[part 1 of 2: package /STELLANTIS/EPT/ASWCs]
AUTOSAR XML (schema 4-2-2)
package /STELLANTIS/EPT/ASWCs
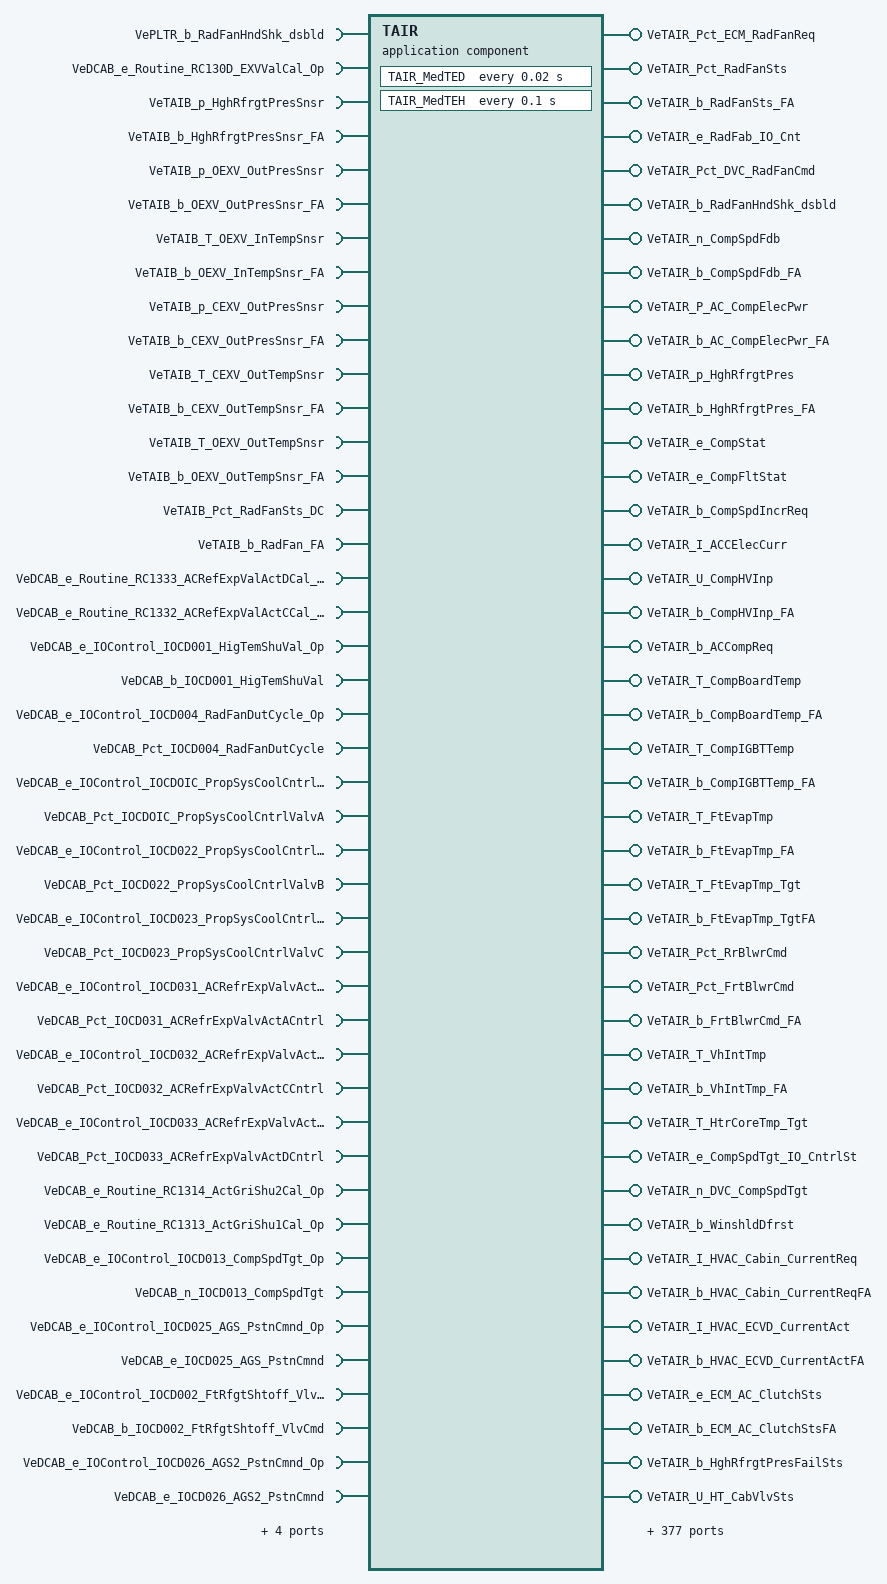
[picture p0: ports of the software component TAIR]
  application sw component type TAIR
    48 x require port:
      VePLTR_b_RadFanHndShk_dsbld: nonqueued-receiver-com-spec{data-element=Value, init-value=0}, required-interface=VePLTR_b_RadFanHndShk_dsbld
      VeDCAB_e_Routine_RC130D_EXVValCal_Op: nonqueued-receiver-com-spec{data-element=Value, init-value=CeDCAB_e_Routine_NOP}, required-interface=VeDCAB_e_Routine_RC130D_EXVValCal_Op
      VeTAIB_p_HghRfrgtPresSnsr: nonqueued-receiver-com-spec{data-element=Value, init-value=0}, required-interface=VeTAIB_p_HghRfrgtPresSnsr
      VeTAIB_b_HghRfrgtPresSnsr_FA: nonqueued-receiver-com-spec{data-element=Value, init-value=0}, required-interface=VeTAIB_b_HghRfrgtPresSnsr_FA
      VeTAIB_p_OEXV_OutPresSnsr: nonqueued-receiver-com-spec{data-element=Value, init-value=0}, required-interface=VeTAIB_p_OEXV_OutPresSnsr
      VeTAIB_b_OEXV_OutPresSnsr_FA: nonqueued-receiver-com-spec{data-element=Value, init-value=0}, required-interface=VeTAIB_b_OEXV_OutPresSnsr_FA
      VeTAIB_T_OEXV_InTempSnsr: nonqueued-receiver-com-spec{data-element=Value, init-value=0}, required-interface=VeTAIB_T_OEXV_InTempSnsr
      VeTAIB_b_OEXV_InTempSnsr_FA: nonqueued-receiver-com-spec{data-element=Value, init-value=0}, required-interface=VeTAIB_b_OEXV_InTempSnsr_FA
      VeTAIB_p_CEXV_OutPresSnsr: nonqueued-receiver-com-spec{data-element=Value, init-value=0}, required-interface=VeTAIB_p_CEXV_OutPresSnsr
      VeTAIB_b_CEXV_OutPresSnsr_FA: nonqueued-receiver-com-spec{data-element=Value, init-value=0}, required-interface=VeTAIB_b_CEXV_OutPresSnsr_FA
      VeTAIB_T_CEXV_OutTempSnsr: nonqueued-receiver-com-spec{data-element=Value, init-value=0}, required-interface=VeTAIB_T_CEXV_OutTempSnsr
      VeTAIB_b_CEXV_OutTempSnsr_FA: nonqueued-receiver-com-spec{data-element=Value, init-value=0}, required-interface=VeTAIB_b_CEXV_OutTempSnsr_FA
      VeTAIB_T_OEXV_OutTempSnsr: nonqueued-receiver-com-spec{data-element=Value, init-value=0}, required-interface=VeTAIB_T_OEXV_OutTempSnsr
      VeTAIB_b_OEXV_OutTempSnsr_FA: nonqueued-receiver-com-spec{data-element=Value, init-value=0}, required-interface=VeTAIB_b_OEXV_OutTempSnsr_FA
      VeTAIB_Pct_RadFanSts_DC: nonqueued-receiver-com-spec{data-element=Value, init-value=0}, required-interface=VeTAIB_Pct_RadFanSts_DC
      VeTAIB_b_RadFan_FA: nonqueued-receiver-com-spec{data-element=Value, init-value=0}, required-interface=VeTAIB_b_RadFan_FA
      VeDCAB_e_Routine_RC1333_ACRefExpValActDCal_Op: nonqueued-receiver-com-spec{data-element=Value, init-value=CeDCAB_e_Routine_NOP}, required-interface=VeDCAB_e_Routine_RC1333_ACRefExpValActDCal_Op
      VeDCAB_e_Routine_RC1332_ACRefExpValActCCal_Op: nonqueued-receiver-com-spec{data-element=Value, init-value=CeDCAB_e_Routine_NOP}, required-interface=VeDCAB_e_Routine_RC1332_ACRefExpValActCCal_Op
      VeDCAB_e_IOControl_IOCD001_HigTemShuVal_Op: nonqueued-receiver-com-spec{data-element=Value, init-value=CeDCAB_e_IO_NOP}, required-interface=VeDCAB_e_IOControl_IOCD001_HigTemShuVal_Op
      VeDCAB_b_IOCD001_HigTemShuVal: nonqueued-receiver-com-spec{data-element=Value, init-value=0}, required-interface=VeDCAB_b_IOCD001_HigTemShuVal
      VeDCAB_e_IOControl_IOCD004_RadFanDutCycle_Op: nonqueued-receiver-com-spec{data-element=Value, init-value=CeDCAB_e_IO_NOP}, required-interface=VeDCAB_e_IOControl_IOCD004_RadFanDutCycle_Op
      VeDCAB_Pct_IOCD004_RadFanDutCycle: nonqueued-receiver-com-spec{data-element=Value, init-value=0}, required-interface=VeDCAB_Pct_IOCD004_RadFanDutCycle
      VeDCAB_e_IOControl_IOCDOIC_PropSysCoolCntrlValvA_Op: nonqueued-receiver-com-spec{data-element=Value, init-value=CeDCAB_e_IO_NOP}, required-interface=VeDCAB_e_IOControl_IOCDOIC_PropSysCoolCntrlValvA_Op
      VeDCAB_Pct_IOCDOIC_PropSysCoolCntrlValvA: nonqueued-receiver-com-spec{data-element=Value, init-value=0}, required-interface=VeDCAB_Pct_IOCDOIC_PropSysCoolCntrlValvA
      VeDCAB_e_IOControl_IOCD022_PropSysCoolCntrlValvB_Op: nonqueued-receiver-com-spec{data-element=Value, init-value=CeDCAB_e_IO_NOP}, required-interface=VeDCAB_e_IOControl_IOCD022_PropSysCoolCntrlValvB_Op
      VeDCAB_Pct_IOCD022_PropSysCoolCntrlValvB: nonqueued-receiver-com-spec{data-element=Value, init-value=0}, required-interface=VeDCAB_Pct_IOCD022_PropSysCoolCntrlValvB
      VeDCAB_e_IOControl_IOCD023_PropSysCoolCntrlValvC_Op: nonqueued-receiver-com-spec{data-element=Value, init-value=CeDCAB_e_IO_NOP}, required-interface=VeDCAB_e_IOControl_IOCD023_PropSysCoolCntrlValvC_Op
      VeDCAB_Pct_IOCD023_PropSysCoolCntrlValvC: nonqueued-receiver-com-spec{data-element=Value, init-value=0}, required-interface=VeDCAB_Pct_IOCD023_PropSysCoolCntrlValvC
      VeDCAB_e_IOControl_IOCD031_ACRefrExpValvActACntrl_Op: nonqueued-receiver-com-spec{data-element=Value, init-value=CeDCAB_e_IO_NOP}, required-interface=VeDCAB_e_IOControl_IOCD031_ACRefrExpValvActACntrl_Op
      VeDCAB_Pct_IOCD031_ACRefrExpValvActACntrl: nonqueued-receiver-com-spec{data-element=Value, init-value=0}, required-interface=VeDCAB_Pct_IOCD031_ACRefrExpValvActACntrl
      VeDCAB_e_IOControl_IOCD032_ACRefrExpValvActCCntrl_Op: nonqueued-receiver-com-spec{data-element=Value, init-value=CeDCAB_e_IO_NOP}, required-interface=VeDCAB_e_IOControl_IOCD032_ACRefrExpValvActCCntrl_Op
      VeDCAB_Pct_IOCD032_ACRefrExpValvActCCntrl: nonqueued-receiver-com-spec{data-element=Value, init-value=0}, required-interface=VeDCAB_Pct_IOCD032_ACRefrExpValvActCCntrl
      VeDCAB_e_IOControl_IOCD033_ACRefrExpValvActDCntrl_Op: nonqueued-receiver-com-spec{data-element=Value, init-value=CeDCAB_e_IO_NOP}, required-interface=VeDCAB_e_IOControl_IOCD033_ACRefrExpValvActDCntrl_Op
      VeDCAB_Pct_IOCD033_ACRefrExpValvActDCntrl: nonqueued-receiver-com-spec{data-element=Value, init-value=0}, required-interface=VeDCAB_Pct_IOCD033_ACRefrExpValvActDCntrl
      VeDCAB_e_Routine_RC1314_ActGriShu2Cal_Op: nonqueued-receiver-com-spec{data-element=Value, init-value=CeDCAB_e_Routine_NOP}, required-interface=VeDCAB_e_Routine_RC1314_ActGriShu2Cal_Op
      VeDCAB_e_Routine_RC1313_ActGriShu1Cal_Op: nonqueued-receiver-com-spec{data-element=Value, init-value=CeDCAB_e_Routine_NOP}, required-interface=VeDCAB_e_Routine_RC1313_ActGriShu1Cal_Op
      VeDCAB_e_IOControl_IOCD013_CompSpdTgt_Op: nonqueued-receiver-com-spec{data-element=Value, init-value=CeDCAB_e_IO_NOP}, required-interface=VeDCAB_e_IOControl_IOCD013_CompSpdTgt_Op
      VeDCAB_n_IOCD013_CompSpdTgt: nonqueued-receiver-com-spec{data-element=Value, init-value=0}, required-interface=VeDCAB_n_IOCD013_CompSpdTgt
      VeDCAB_e_IOControl_IOCD025_AGS_PstnCmnd_Op: nonqueued-receiver-com-spec{data-element=Value, init-value=CeDCAB_e_IO_NOP}, required-interface=VeDCAB_e_IOControl_IOCD025_AGS_PstnCmnd_Op
      VeDCAB_e_IOCD025_AGS_PstnCmnd: nonqueued-receiver-com-spec{data-element=Value, init-value=CeFSCR_e_Open100}, required-interface=VeDCAB_e_IOCD025_AGS_PstnCmnd
      VeDCAB_e_IOControl_IOCD002_FtRfgtShtoff_VlvCmd_Op: nonqueued-receiver-com-spec{data-element=Value, init-value=CeDCAB_e_IO_NOP}, required-interface=VeDCAB_e_IOControl_IOCD002_FtRfgtShtoff_VlvCmd_Op
      VeDCAB_b_IOCD002_FtRfgtShtoff_VlvCmd: nonqueued-receiver-com-spec{data-element=Value, init-value=0}, required-interface=VeDCAB_b_IOCD002_FtRfgtShtoff_VlvCmd
      VeDCAB_e_IOControl_IOCD026_AGS2_PstnCmnd_Op: nonqueued-receiver-com-spec{data-element=Value, init-value=CeDCAB_e_IO_NOP}, required-interface=VeDCAB_e_IOControl_IOCD026_AGS2_PstnCmnd_Op
      VeDCAB_e_IOCD026_AGS2_PstnCmnd: nonqueued-receiver-com-spec{data-element=Value, init-value=CeFSCR_e_Open100}, required-interface=VeDCAB_e_IOCD026_AGS2_PstnCmnd
      VeDCAB_e_IOControl_IOCD01F_ACRefrExpValvActACntrl_Op: nonqueued-receiver-com-spec{data-element=Value, init-value=CeDCAB_e_IO_NOP}, required-interface=VeDCAB_e_IOControl_IOCD01F_ACRefrExpValvActACntrl_Op
      VeDCAB_Pct_IOCD01F_ACRefrExpValvActACntrl: nonqueued-receiver-com-spec{data-element=Value, init-value=0}, required-interface=VeDCAB_Pct_IOCD01F_ACRefrExpValvActACntrl
      VeDCAB_e_IOControl_IOCD007_ChlrRfgtShtoff_VlvCmd_Op: nonqueued-receiver-com-spec{data-element=Value, init-value=CeDCAB_e_IO_NOP}, required-interface=VeDCAB_e_IOControl_IOCD007_ChlrRfgtShtoff_VlvCmd_Op
      VeDCAB_b_IOCD007_ChlrRfgtShtoff_VlvCmd: nonqueued-receiver-com-spec{data-element=Value, init-value=0}, required-interface=VeDCAB_b_IOCD007_ChlrRfgtShtoff_VlvCmd
    421 x provide port:
      VeTAIR_Pct_ECM_RadFanReq: nonqueued-sender-com-spec{data-element=Value, init-value=0}, provided-interface=VeTAIR_Pct_ECM_RadFanReq
      VeTAIR_Pct_RadFanSts: nonqueued-sender-com-spec{data-element=Value, init-value=0}, provided-interface=VeTAIR_Pct_RadFanSts
      VeTAIR_b_RadFanSts_FA: nonqueued-sender-com-spec{data-element=Value, init-value=0}, provided-interface=VeTAIR_b_RadFanSts_FA
      VeTAIR_e_RadFab_IO_Cnt: nonqueued-sender-com-spec{data-element=Value, init-value=CeTAIR_e_Return_Control_to_ECU}, provided-interface=VeTAIR_e_RadFab_IO_Cnt
      VeTAIR_Pct_DVC_RadFanCmd: nonqueued-sender-com-spec{data-element=Value, init-value=0}, provided-interface=VeTAIR_Pct_DVC_RadFanCmd
      VeTAIR_b_RadFanHndShk_dsbld: nonqueued-sender-com-spec{data-element=Value, init-value=0}, provided-interface=VeTAIR_b_RadFanHndShk_dsbld
      VeTAIR_n_CompSpdFdb: nonqueued-sender-com-spec{data-element=Value, init-value=0}, provided-interface=VeTAIR_n_CompSpdFdb
      VeTAIR_b_CompSpdFdb_FA: nonqueued-sender-com-spec{data-element=Value, init-value=0}, provided-interface=VeTAIR_b_CompSpdFdb_FA
      VeTAIR_P_AC_CompElecPwr: nonqueued-sender-com-spec{data-element=Value, init-value=0}, provided-interface=VeTAIR_P_AC_CompElecPwr
      VeTAIR_b_AC_CompElecPwr_FA: nonqueued-sender-com-spec{data-element=Value, init-value=0}, provided-interface=VeTAIR_b_AC_CompElecPwr_FA
      VeTAIR_p_HghRfrgtPres: nonqueued-sender-com-spec{data-element=Value, init-value=0}, provided-interface=VeTAIR_p_HghRfrgtPres
      VeTAIR_b_HghRfrgtPres_FA: nonqueued-sender-com-spec{data-element=Value, init-value=0}, provided-interface=VeTAIR_b_HghRfrgtPres_FA
      VeTAIR_e_CompStat: nonqueued-sender-com-spec{data-element=Value, init-value=CeTAIR_e_NormalOp}, provided-interface=VeTAIR_e_CompStat
      VeTAIR_e_CompFltStat: nonqueued-sender-com-spec{data-element=Value, init-value=CeTAIR_e_CompFltSts_NoFault}, provided-interface=VeTAIR_e_CompFltStat
      VeTAIR_b_CompSpdIncrReq: nonqueued-sender-com-spec{data-element=Value, init-value=0}, provided-interface=VeTAIR_b_CompSpdIncrReq
      VeTAIR_I_ACCElecCurr: nonqueued-sender-com-spec{data-element=Value, init-value=0}, provided-interface=VeTAIR_I_ACCElecCurr
      VeTAIR_U_CompHVInp: nonqueued-sender-com-spec{data-element=Value, init-value=0}, provided-interface=VeTAIR_U_CompHVInp
      VeTAIR_b_CompHVInp_FA: nonqueued-sender-com-spec{data-element=Value, init-value=0}, provided-interface=VeTAIR_b_CompHVInp_FA
      VeTAIR_b_ACCompReq: nonqueued-sender-com-spec{data-element=Value, init-value=0}, provided-interface=VeTAIR_b_ACCompReq
      VeTAIR_T_CompBoardTemp: nonqueued-sender-com-spec{data-element=Value, init-value=0}, provided-interface=VeTAIR_T_CompBoardTemp
      VeTAIR_b_CompBoardTemp_FA: nonqueued-sender-com-spec{data-element=Value, init-value=0}, provided-interface=VeTAIR_b_CompBoardTemp_FA
      VeTAIR_T_CompIGBTTemp: nonqueued-sender-com-spec{data-element=Value, init-value=0}, provided-interface=VeTAIR_T_CompIGBTTemp
      VeTAIR_b_CompIGBTTemp_FA: nonqueued-sender-com-spec{data-element=Value, init-value=0}, provided-interface=VeTAIR_b_CompIGBTTemp_FA
      VeTAIR_T_FtEvapTmp: nonqueued-sender-com-spec{data-element=Value, init-value=0}, provided-interface=VeTAIR_T_FtEvapTmp
      VeTAIR_b_FtEvapTmp_FA: nonqueued-sender-com-spec{data-element=Value, init-value=0}, provided-interface=VeTAIR_b_FtEvapTmp_FA
      VeTAIR_T_FtEvapTmp_Tgt: nonqueued-sender-com-spec{data-element=Value, init-value=0}, provided-interface=VeTAIR_T_FtEvapTmp_Tgt
      VeTAIR_b_FtEvapTmp_TgtFA: nonqueued-sender-com-spec{data-element=Value, init-value=0}, provided-interface=VeTAIR_b_FtEvapTmp_TgtFA
      VeTAIR_Pct_RrBlwrCmd: nonqueued-sender-com-spec{data-element=Value, init-value=0}, provided-interface=VeTAIR_Pct_RrBlwrCmd
      VeTAIR_Pct_FrtBlwrCmd: nonqueued-sender-com-spec{data-element=Value, init-value=0}, provided-interface=VeTAIR_Pct_FrtBlwrCmd
      VeTAIR_b_FrtBlwrCmd_FA: nonqueued-sender-com-spec{data-element=Value, init-value=0}, provided-interface=VeTAIR_b_FrtBlwrCmd_FA
      VeTAIR_T_VhIntTmp: nonqueued-sender-com-spec{data-element=Value, init-value=0}, provided-interface=VeTAIR_T_VhIntTmp
      VeTAIR_b_VhIntTmp_FA: nonqueued-sender-com-spec{data-element=Value, init-value=0}, provided-interface=VeTAIR_b_VhIntTmp_FA
      VeTAIR_T_HtrCoreTmp_Tgt: nonqueued-sender-com-spec{data-element=Value, init-value=0}, provided-interface=VeTAIR_T_HtrCoreTmp_Tgt
      VeTAIR_e_CompSpdTgt_IO_CntrlSt: nonqueued-sender-com-spec{data-element=Value, init-value=CeTAIR_e_Return_Control_to_ECU}, provided-interface=VeTAIR_e_CompSpdTgt_IO_CntrlSt
      VeTAIR_n_DVC_CompSpdTgt: nonqueued-sender-com-spec{data-element=Value, init-value=0}, provided-interface=VeTAIR_n_DVC_CompSpdTgt
      VeTAIR_b_WinshldDfrst: nonqueued-sender-com-spec{data-element=Value, init-value=0}, provided-interface=VeTAIR_b_WinshldDfrst
      VeTAIR_I_HVAC_Cabin_CurrentReq: nonqueued-sender-com-spec{data-element=Value, init-value=0}, provided-interface=VeTAIR_I_HVAC_Cabin_CurrentReq
      VeTAIR_b_HVAC_Cabin_CurrentReqFA: nonqueued-sender-com-spec{data-element=Value, init-value=0}, provided-interface=VeTAIR_b_HVAC_Cabin_CurrentReqFA
      VeTAIR_I_HVAC_ECVD_CurrentAct: nonqueued-sender-com-spec{data-element=Value, init-value=0}, provided-interface=VeTAIR_I_HVAC_ECVD_CurrentAct
      VeTAIR_b_HVAC_ECVD_CurrentActFA: nonqueued-sender-com-spec{data-element=Value, init-value=0}, provided-interface=VeTAIR_b_HVAC_ECVD_CurrentActFA
      VeTAIR_e_ECM_AC_ClutchSts: nonqueued-sender-com-spec{data-element=Value, init-value=CeTAIR_e_ClutchSts_Default}, provided-interface=VeTAIR_e_ECM_AC_ClutchSts
      VeTAIR_b_ECM_AC_ClutchStsFA: nonqueued-sender-com-spec{data-element=Value, init-value=0}, provided-interface=VeTAIR_b_ECM_AC_ClutchStsFA
      VeTAIR_b_HghRfrgtPresFailSts: nonqueued-sender-com-spec{data-element=Value, init-value=0}, provided-interface=VeTAIR_b_HghRfrgtPresFailSts
      VeTAIR_U_HT_CabVlvSts: nonqueued-sender-com-spec{data-element=Value, init-value=0}, provided-interface=VeTAIR_U_HT_CabVlvSts
      VeTAIR_b_HT_CabVlvSts_FA: nonqueued-sender-com-spec{data-element=Value, init-value=0}, provided-interface=VeTAIR_b_HT_CabVlvSts_FA
      VeTAIR_e_DVC_HTCV_CalibStrt: nonqueued-sender-com-spec{data-element=Value, init-value=CeTAIR_e_DVC_HTCV_Calibration_Start}, provided-interface=VeTAIR_e_DVC_HTCV_CalibStrt
      VeTAIR_e_HT_Shtoff_VlvCmd_IO_CntrlSt: nonqueued-sender-com-spec{data-element=Value, init-value=CeTAIR_e_Return_Control_to_ECU}, provided-interface=VeTAIR_e_HT_Shtoff_VlvCmd_IO_CntrlSt
      VeTAIR_b_HT_Shtoff_VlvCmd: nonqueued-sender-com-spec{data-element=Value, init-value=0}, provided-interface=VeTAIR_b_HT_Shtoff_VlvCmd
      VeTAIR_e_Ft_SO_VlvCmd_IO_Cnt: nonqueued-sender-com-spec{data-element=Value, init-value=CeTAIR_e_Return_Control_to_ECU}, provided-interface=VeTAIR_e_Ft_SO_VlvCmd_IO_Cnt
      VeTAIR_b_Ft_SO_VlvCmd: nonqueued-sender-com-spec{data-element=Value, init-value=0}, provided-interface=VeTAIR_b_Ft_SO_VlvCmd
      VeTAIR_e_Chlr_SO_VlvCmd_IO_Cnt: nonqueued-sender-com-spec{data-element=Value, init-value=CeTAIR_e_Return_Control_to_ECU}, provided-interface=VeTAIR_e_Chlr_SO_VlvCmd_IO_Cnt
      VeTAIR_b_Chlr_SO_VlvCmd: nonqueued-sender-com-spec{data-element=Value, init-value=0}, provided-interface=VeTAIR_b_Chlr_SO_VlvCmd
      VeTAIR_e_HT_CabVlvCmd_IO_Cnt: nonqueued-sender-com-spec{data-element=Value, init-value=CeTAIR_e_Return_Control_to_ECU}, provided-interface=VeTAIR_e_HT_CabVlvCmd_IO_Cnt
      VeTAIR_Pct_HT_CabVlvCmd: nonqueued-sender-com-spec{data-element=Value, init-value=0}, provided-interface=VeTAIR_Pct_HT_CabVlvCmd
      VeTAIR_Pct_FrWyVlv_PstnAct: nonqueued-sender-com-spec{data-element=Value, init-value=0}, provided-interface=VeTAIR_Pct_FrWyVlv_PstnAct
      VeTAIR_b_FrWyVlv_PstnAct_FA: nonqueued-sender-com-spec{data-element=Value, init-value=0}, provided-interface=VeTAIR_b_FrWyVlv_PstnAct_FA
      VeTAIR_e_FrWyVlv_CalSts: nonqueued-sender-com-spec{data-element=Value, init-value=CeTAIR_e_CPV_Calibration_Complete}, provided-interface=VeTAIR_e_FrWyVlv_CalSts
      VeTAIR_b_FrWyVlv_RsErr: nonqueued-sender-com-spec{data-element=Value, init-value=0}, provided-interface=VeTAIR_b_FrWyVlv_RsErr
      VeTAIR_e_FrWyVlv_ErrSts: nonqueued-sender-com-spec{data-element=Value, init-value=CeTAIR_e_CPV_Status_OK}, provided-interface=VeTAIR_e_FrWyVlv_ErrSts
      VeTAIR_U_FrWyVlv_MtrVltg: nonqueued-sender-com-spec{data-element=Value, init-value=0}, provided-interface=VeTAIR_U_FrWyVlv_MtrVltg
      VeTAIR_e_CPV_IO_Cnt: nonqueued-sender-com-spec{data-element=Value, init-value=CeTAIR_e_Return_Control_to_ECU}, provided-interface=VeTAIR_e_CPV_IO_Cnt
      VeTAIR_Pct_CPV_Cmd: nonqueued-sender-com-spec{data-element=Value, init-value=0}, provided-interface=VeTAIR_Pct_CPV_Cmd
      VeTAIR_Pct_EXV_PosAct: nonqueued-sender-com-spec{data-element=Value, init-value=0}, provided-interface=VeTAIR_Pct_EXV_PosAct
      VeTAIR_b_EXV_PosAct_FA: nonqueued-sender-com-spec{data-element=Value, init-value=0}, provided-interface=VeTAIR_b_EXV_PosAct_FA
      VeTAIR_e_EXV_CalStat: nonqueued-sender-com-spec{data-element=Value, init-value=CeTAIR_e_EXV_Calibration_Complete}, provided-interface=VeTAIR_e_EXV_CalStat
      VeTAIR_b_EXV_CalRq: nonqueued-sender-com-spec{data-element=Value, init-value=0}, provided-interface=VeTAIR_b_EXV_CalRq
      VeTAIR_b_EXV_RspErr: nonqueued-sender-com-spec{data-element=Value, init-value=0}, provided-interface=VeTAIR_b_EXV_RspErr
      VeTAIR_e_EXV_Sts: nonqueued-sender-com-spec{data-element=Value, init-value=CeTAIR_e_EXV_Status_OK}, provided-interface=VeTAIR_e_EXV_Sts
      VeTAIR_e_EXV_Err: nonqueued-sender-com-spec{data-element=Value, init-value=CeTAIR_e_EXV_ErrorMsg_OK}, provided-interface=VeTAIR_e_EXV_Err
      VeTAIR_U_EXV_SupplyVolt: nonqueued-sender-com-spec{data-element=Value, init-value=0}, provided-interface=VeTAIR_U_EXV_SupplyVolt
      VeTAIR_p_EXV_RefPress: nonqueued-sender-com-spec{data-element=Value, init-value=0}, provided-interface=VeTAIR_p_EXV_RefPress
      VeTAIR_b_EXV_RefPress_FA: nonqueued-sender-com-spec{data-element=Value, init-value=0}, provided-interface=VeTAIR_b_EXV_RefPress_FA
      VeTAIR_T_EXV_BoardTemp: nonqueued-sender-com-spec{data-element=Value, init-value=0}, provided-interface=VeTAIR_T_EXV_BoardTemp
      VeTAIR_T_EXV_RefTemp: nonqueued-sender-com-spec{data-element=Value, init-value=0}, provided-interface=VeTAIR_T_EXV_RefTemp
      VeTAIR_b_EXV_RefTemp_FA: nonqueued-sender-com-spec{data-element=Value, init-value=0}, provided-interface=VeTAIR_b_EXV_RefTemp_FA
      VeTAIR_b_FrWyVlv_OvrVltg: nonqueued-sender-com-spec{data-element=Value, init-value=0}, provided-interface=VeTAIR_b_FrWyVlv_OvrVltg
      VeTAIR_b_FrWyVlv_UndrVltg: nonqueued-sender-com-spec{data-element=Value, init-value=0}, provided-interface=VeTAIR_b_FrWyVlv_UndrVltg
      VeTAIR_b_FrWyVlv_ThrmlWrng: nonqueued-sender-com-spec{data-element=Value, init-value=0}, provided-interface=VeTAIR_b_FrWyVlv_ThrmlWrng
      VeTAIR_b_FrWyVlv_OpnLd: nonqueued-sender-com-spec{data-element=Value, init-value=0}, provided-interface=VeTAIR_b_FrWyVlv_OpnLd
      VeTAIR_b_FrWyVlv_OvrCrnt: nonqueued-sender-com-spec{data-element=Value, init-value=0}, provided-interface=VeTAIR_b_FrWyVlv_OvrCrnt
      VeTAIR_b_FrWyVlv_MechBrk: nonqueued-sender-com-spec{data-element=Value, init-value=0}, provided-interface=VeTAIR_b_FrWyVlv_MechBrk
      VeTAIR_b_FrWyVlv_BlckPnt: nonqueued-sender-com-spec{data-element=Value, init-value=0}, provided-interface=VeTAIR_b_FrWyVlv_BlckPnt
      VeTAIR_b_FrWyVlv_Err_SNA: nonqueued-sender-com-spec{data-element=Value, init-value=0}, provided-interface=VeTAIR_b_FrWyVlv_Err_SNA
      VeTAIR_Pct_LTR_BypsVlv_ActlPstn: nonqueued-sender-com-spec{data-element=Value, init-value=0}, provided-interface=VeTAIR_Pct_LTR_BypsVlv_ActlPstn
      VeTAIR_b_LTR_BypsVlv_ActlPstn_FA: nonqueued-sender-com-spec{data-element=Value, init-value=0}, provided-interface=VeTAIR_b_LTR_BypsVlv_ActlPstn_FA
      VeTAIR_e_LTR_BypsVlv_CalSts: nonqueued-sender-com-spec{data-element=Value, init-value=CeTAIR_e_CPV_Calibration_Complete}, provided-interface=VeTAIR_e_LTR_BypsVlv_CalSts
      VeTAIR_b_LTR_BypsVlv_CalSts_FA: nonqueued-sender-com-spec{data-element=Value, init-value=0}, provided-interface=VeTAIR_b_LTR_BypsVlv_CalSts_FA
      VeTAIR_b_LTR_BypsVlv_RsErr: nonqueued-sender-com-spec{data-element=Value, init-value=0}, provided-interface=VeTAIR_b_LTR_BypsVlv_RsErr
      VeTAIR_e_LTR_BypsVlv_ErrSts: nonqueued-sender-com-spec{data-element=Value, init-value=CeTAIR_e_CPV_Status_OK}, provided-interface=VeTAIR_e_LTR_BypsVlv_ErrSts
      VeTAIR_b_LTR_BypsVlv_ErrSts_FA: nonqueued-sender-com-spec{data-element=Value, init-value=0}, provided-interface=VeTAIR_b_LTR_BypsVlv_ErrSts_FA
      VeTAIR_U_LTR_BypsVlv_MtrVltg: nonqueued-sender-com-spec{data-element=Value, init-value=0}, provided-interface=VeTAIR_U_LTR_BypsVlv_MtrVltg
      VeTAIR_b_LTR_BypsVlv_MtrVltg_FA: nonqueued-sender-com-spec{data-element=Value, init-value=0}, provided-interface=VeTAIR_b_LTR_BypsVlv_MtrVltg_FA
      VeTAIR_Pct_HTL_BypsVlv_ActlPstn: nonqueued-sender-com-spec{data-element=Value, init-value=0}, provided-interface=VeTAIR_Pct_HTL_BypsVlv_ActlPstn
      VeTAIR_b_HTL_BypsVlv_ActlPstn_FA: nonqueued-sender-com-spec{data-element=Value, init-value=0}, provided-interface=VeTAIR_b_HTL_BypsVlv_ActlPstn_FA
      VeTAIR_e_HTL_BypsVlv_CalSts: nonqueued-sender-com-spec{data-element=Value, init-value=CeTAIR_e_CPV_Calibration_Complete}, provided-interface=VeTAIR_e_HTL_BypsVlv_CalSts
      VeTAIR_b_HTL_BypsVlv_CalSts_FA: nonqueued-sender-com-spec{data-element=Value, init-value=0}, provided-interface=VeTAIR_b_HTL_BypsVlv_CalSts_FA
      VeTAIR_b_HTL_BypsVlv_RsErr: nonqueued-sender-com-spec{data-element=Value, init-value=0}, provided-interface=VeTAIR_b_HTL_BypsVlv_RsErr
      VeTAIR_e_HTL_BypsVlv_ErrSts: nonqueued-sender-com-spec{data-element=Value, init-value=CeTAIR_e_CPV_Status_OK}, provided-interface=VeTAIR_e_HTL_BypsVlv_ErrSts
      VeTAIR_b_HTL_BypsVlv_ErrSts_FA: nonqueued-sender-com-spec{data-element=Value, init-value=0}, provided-interface=VeTAIR_b_HTL_BypsVlv_ErrSts_FA
      VeTAIR_U_HTL_BypsVlv_MtrVltg: nonqueued-sender-com-spec{data-element=Value, init-value=0}, provided-interface=VeTAIR_U_HTL_BypsVlv_MtrVltg
      VeTAIR_b_HTL_BypsVlv_MtrVltg_FA: nonqueued-sender-com-spec{data-element=Value, init-value=0}, provided-interface=VeTAIR_b_HTL_BypsVlv_MtrVltg_FA
      VeTAIR_e_EXV_IO_CntrlSt: nonqueued-sender-com-spec{data-element=Value, init-value=CeTAIR_e_Return_Control_to_ECU}, provided-interface=VeTAIR_e_EXV_IO_CntrlSt
      VeTAIR_Pct_EXV_Cmd: nonqueued-sender-com-spec{data-element=Value, init-value=0}, provided-interface=VeTAIR_Pct_EXV_Cmd
      VeTAIR_b_DVC_EXV_Calibration_Start: nonqueued-sender-com-spec{data-element=Value, init-value=0}, provided-interface=VeTAIR_b_DVC_EXV_Calibration_Start
      VeTAIR_e_LT_Shtoff_VlvCmd_IO_CntrlSt: nonqueued-sender-com-spec{data-element=Value, init-value=CeTAIR_e_Return_Control_to_ECU}, provided-interface=VeTAIR_e_LT_Shtoff_VlvCmd_IO_CntrlSt
      VeTAIR_b_LT_Shtoff_VlvCmd: nonqueued-sender-com-spec{data-element=Value, init-value=0}, provided-interface=VeTAIR_b_LT_Shtoff_VlvCmd
      VeTAIR_Pct_LTR_BypsVlv_Cmd: nonqueued-sender-com-spec{data-element=Value, init-value=0}, provided-interface=VeTAIR_Pct_LTR_BypsVlv_Cmd
      VeTAIR_e_LTR_BypsVlv_IO_CntrlSt: nonqueued-sender-com-spec{data-element=Value, init-value=CeTAIR_e_Return_Control_to_ECU}, provided-interface=VeTAIR_e_LTR_BypsVlv_IO_CntrlSt
      VeTAIR_Pct_HTL_BypsVlv_Cmd: nonqueued-sender-com-spec{data-element=Value, init-value=0}, provided-interface=VeTAIR_Pct_HTL_BypsVlv_Cmd
      VeTAIR_e_HTL_BypsVlv_IO_CntrlSt: nonqueued-sender-com-spec{data-element=Value, init-value=CeTAIR_e_Return_Control_to_ECU}, provided-interface=VeTAIR_e_HTL_BypsVlv_IO_CntrlSt
      VeTAIR_b_LTR_BypsVlv_OvrVltg: nonqueued-sender-com-spec{data-element=Value, init-value=0}, provided-interface=VeTAIR_b_LTR_BypsVlv_OvrVltg
      VeTAIR_b_LTR_BypsVlv_UndrVltg: nonqueued-sender-com-spec{data-element=Value, init-value=0}, provided-interface=VeTAIR_b_LTR_BypsVlv_UndrVltg
      VeTAIR_b_LTR_BypsVlv_ThrmlWrng: nonqueued-sender-com-spec{data-element=Value, init-value=0}, provided-interface=VeTAIR_b_LTR_BypsVlv_ThrmlWrng
      VeTAIR_b_LTR_BypsVlv_OpnLd: nonqueued-sender-com-spec{data-element=Value, init-value=0}, provided-interface=VeTAIR_b_LTR_BypsVlv_OpnLd
      VeTAIR_b_LTR_BypsVlv_OvrCrnt: nonqueued-sender-com-spec{data-element=Value, init-value=0}, provided-interface=VeTAIR_b_LTR_BypsVlv_OvrCrnt
      VeTAIR_b_LTR_BypsVlv_MechBrk: nonqueued-sender-com-spec{data-element=Value, init-value=0}, provided-interface=VeTAIR_b_LTR_BypsVlv_MechBrk
      VeTAIR_b_LTR_BypsVlv_BlckPnt: nonqueued-sender-com-spec{data-element=Value, init-value=0}, provided-interface=VeTAIR_b_LTR_BypsVlv_BlckPnt
      VeTAIR_b_LTR_BypsVlv_Err_SNA: nonqueued-sender-com-spec{data-element=Value, init-value=0}, provided-interface=VeTAIR_b_LTR_BypsVlv_Err_SNA
      VeTAIR_b_HTL_BypsVlv_OvrVltg: nonqueued-sender-com-spec{data-element=Value, init-value=0}, provided-interface=VeTAIR_b_HTL_BypsVlv_OvrVltg
      VeTAIR_b_HTL_BypsVlv_UndrVltg: nonqueued-sender-com-spec{data-element=Value, init-value=0}, provided-interface=VeTAIR_b_HTL_BypsVlv_UndrVltg
      VeTAIR_b_HTL_BypsVlv_ThrmlWrng: nonqueued-sender-com-spec{data-element=Value, init-value=0}, provided-interface=VeTAIR_b_HTL_BypsVlv_ThrmlWrng
      VeTAIR_b_HTL_BypsVlv_OpnLd: nonqueued-sender-com-spec{data-element=Value, init-value=0}, provided-interface=VeTAIR_b_HTL_BypsVlv_OpnLd
      VeTAIR_b_HTL_BypsVlv_OvrCrnt: nonqueued-sender-com-spec{data-element=Value, init-value=0}, provided-interface=VeTAIR_b_HTL_BypsVlv_OvrCrnt
      VeTAIR_b_HTL_BypsVlv_MechBrk: nonqueued-sender-com-spec{data-element=Value, init-value=0}, provided-interface=VeTAIR_b_HTL_BypsVlv_MechBrk
      VeTAIR_b_HTL_BypsVlv_BlckPnt: nonqueued-sender-com-spec{data-element=Value, init-value=0}, provided-interface=VeTAIR_b_HTL_BypsVlv_BlckPnt
      VeTAIR_b_HTL_BypsVlv_Err_SNA: nonqueued-sender-com-spec{data-element=Value, init-value=0}, provided-interface=VeTAIR_b_HTL_BypsVlv_Err_SNA
      VeTAIR_Pct_EEXV_PosAct: nonqueued-sender-com-spec{data-element=Value, init-value=0}, provided-interface=VeTAIR_Pct_EEXV_PosAct
      VeTAIR_b_EEXV_PosAct_FA: nonqueued-sender-com-spec{data-element=Value, init-value=0}, provided-interface=VeTAIR_b_EEXV_PosAct_FA
      VeTAIR_e_EEXV_CalStat: nonqueued-sender-com-spec{data-element=Value, init-value=CeTAIR_e_EXV_Calibration_Complete}, provided-interface=VeTAIR_e_EEXV_CalStat
      VeTAIR_b_EEXV_CalRq: nonqueued-sender-com-spec{data-element=Value, init-value=0}, provided-interface=VeTAIR_b_EEXV_CalRq
      VeTAIR_b_EEXV_RspErr: nonqueued-sender-com-spec{data-element=Value, init-value=0}, provided-interface=VeTAIR_b_EEXV_RspErr
      VeTAIR_e_EEXV_Sts: nonqueued-sender-com-spec{data-element=Value, init-value=CeTAIR_e_EXV_Status_OK}, provided-interface=VeTAIR_e_EEXV_Sts
      VeTAIR_e_EEXV_Err: nonqueued-sender-com-spec{data-element=Value, init-value=CeTAIR_e_EXV_ErrorMsg_OK}, provided-interface=VeTAIR_e_EEXV_Err
      VeTAIR_U_EEXV_SupplyVolt: nonqueued-sender-com-spec{data-element=Value, init-value=0}, provided-interface=VeTAIR_U_EEXV_SupplyVolt
      VeTAIR_p_EEXV_RefPress: nonqueued-sender-com-spec{data-element=Value, init-value=0}, provided-interface=VeTAIR_p_EEXV_RefPress
      VeTAIR_b_EEXV_RefPress_FA: nonqueued-sender-com-spec{data-element=Value, init-value=0}, provided-interface=VeTAIR_b_EEXV_RefPress_FA
      VeTAIR_T_EEXV_BoardTemp: nonqueued-sender-com-spec{data-element=Value, init-value=0}, provided-interface=VeTAIR_T_EEXV_BoardTemp
      VeTAIR_T_EEXV_RefTemp: nonqueued-sender-com-spec{data-element=Value, init-value=0}, provided-interface=VeTAIR_T_EEXV_RefTemp
      VeTAIR_b_EEXV_RefTemp_FA: nonqueued-sender-com-spec{data-element=Value, init-value=0}, provided-interface=VeTAIR_b_EEXV_RefTemp_FA
      VeTAIR_Pct_OEXV_PosAct: nonqueued-sender-com-spec{data-element=Value, init-value=0}, provided-interface=VeTAIR_Pct_OEXV_PosAct
      VeTAIR_b_OEXV_PosAct_FA: nonqueued-sender-com-spec{data-element=Value, init-value=0}, provided-interface=VeTAIR_b_OEXV_PosAct_FA
      VeTAIR_e_OEXV_CalStat: nonqueued-sender-com-spec{data-element=Value, init-value=CeTAIR_e_EXV_Calibration_Complete}, provided-interface=VeTAIR_e_OEXV_CalStat
      VeTAIR_b_OEXV_CalRq: nonqueued-sender-com-spec{data-element=Value, init-value=0}, provided-interface=VeTAIR_b_OEXV_CalRq
      VeTAIR_b_OEXV_RspErr: nonqueued-sender-com-spec{data-element=Value, init-value=0}, provided-interface=VeTAIR_b_OEXV_RspErr
      VeTAIR_e_OEXV_Sts: nonqueued-sender-com-spec{data-element=Value, init-value=CeTAIR_e_EXV_Status_OK}, provided-interface=VeTAIR_e_OEXV_Sts
      VeTAIR_e_OEXV_Err: nonqueued-sender-com-spec{data-element=Value, init-value=CeTAIR_e_EXV_ErrorMsg_OK}, provided-interface=VeTAIR_e_OEXV_Err
      VeTAIR_U_OEXV_SupplyVolt: nonqueued-sender-com-spec{data-element=Value, init-value=0}, provided-interface=VeTAIR_U_OEXV_SupplyVolt
      VeTAIR_p_OEXV_OutPressSens: nonqueued-sender-com-spec{data-element=Value, init-value=0}, provided-interface=VeTAIR_p_OEXV_OutPressSens
      VeTAIR_b_OEXV_OutPressSens_FA: nonqueued-sender-com-spec{data-element=Value, init-value=0}, provided-interface=VeTAIR_b_OEXV_OutPressSens_FA
      VeTAIR_T_OEXV_BoardTemp: nonqueued-sender-com-spec{data-element=Value, init-value=0}, provided-interface=VeTAIR_T_OEXV_BoardTemp
      VeTAIR_T_OEXV_OutTempSens: nonqueued-sender-com-spec{data-element=Value, init-value=0}, provided-interface=VeTAIR_T_OEXV_OutTempSens
      VeTAIR_b_OEXV_OutTempSens_FA: nonqueued-sender-com-spec{data-element=Value, init-value=0}, provided-interface=VeTAIR_b_OEXV_OutTempSens_FA
      VeTAIR_T_OEXV_InTempSens: nonqueued-sender-com-spec{data-element=Value, init-value=0}, provided-interface=VeTAIR_T_OEXV_InTempSens
      VeTAIR_b_OEXV_InTempSens_FA: nonqueued-sender-com-spec{data-element=Value, init-value=0}, provided-interface=VeTAIR_b_OEXV_InTempSens_FA
      VeTAIR_T_CEXV_OutTempSens: nonqueued-sender-com-spec{data-element=Value, init-value=0}, provided-interface=VeTAIR_T_CEXV_OutTempSens
      VeTAIR_b_CEXV_OutTempSens_FA: nonqueued-sender-com-spec{data-element=Value, init-value=0}, provided-interface=VeTAIR_b_CEXV_OutTempSens_FA
      VeTAIR_p_CEXV_OutPressSens: nonqueued-sender-com-spec{data-element=Value, init-value=0}, provided-interface=VeTAIR_p_CEXV_OutPressSens
      VeTAIR_b_CEXV_OutPressSens_FA: nonqueued-sender-com-spec{data-element=Value, init-value=0}, provided-interface=VeTAIR_b_CEXV_OutPressSens_FA
      VeTAIR_b_AGS_BoostSts: nonqueued-sender-com-spec{data-element=Value, init-value=0}, provided-interface=VeTAIR_b_AGS_BoostSts
      VeTAIR_b_AGS_CalibrationActv: nonqueued-sender-com-spec{data-element=Value, init-value=0}, provided-interface=VeTAIR_b_AGS_CalibrationActv
      VeTAIR_b_AGS_ErrMechBreak: nonqueued-sender-com-spec{data-element=Value, init-value=0}, provided-interface=VeTAIR_b_AGS_ErrMechBreak
      VeTAIR_b_AGS_ErrMechStuck: nonqueued-sender-com-spec{data-element=Value, init-value=0}, provided-interface=VeTAIR_b_AGS_ErrMechStuck
      VeTAIR_b_AGS_ErrOverTemp: nonqueued-sender-com-spec{data-element=Value, init-value=0}, provided-interface=VeTAIR_b_AGS_ErrOverTemp
      VeTAIR_b_AGS_ErrOverVolt: nonqueued-sender-com-spec{data-element=Value, init-value=0}, provided-interface=VeTAIR_b_AGS_ErrOverVolt
      VeTAIR_b_AGS_ErrFdbFA: nonqueued-sender-com-spec{data-element=Value, init-value=0}, provided-interface=VeTAIR_b_AGS_ErrFdbFA
      VeTAIR_e_AGS_ErrFdb: nonqueued-sender-com-spec{data-element=Value, init-value=CeTAIR_e_AGS_NO_ERROR}, provided-interface=VeTAIR_e_AGS_ErrFdb
      VeTAIR_b_AGS_CurrPosFA: nonqueued-sender-com-spec{data-element=Value, init-value=0}, provided-interface=VeTAIR_b_AGS_CurrPosFA
      VeTAIR_Pct_AGS_CurrPos: nonqueued-sender-com-spec{data-element=Value, init-value=0}, provided-interface=VeTAIR_Pct_AGS_CurrPos
      VeTAIR_b_AGS_ResErr: nonqueued-sender-com-spec{data-element=Value, init-value=0}, provided-interface=VeTAIR_b_AGS_ResErr
      VeTAIR_b_AGS_ErrUnderVolt: nonqueued-sender-com-spec{data-element=Value, init-value=0}, provided-interface=VeTAIR_b_AGS_ErrUnderVolt
      VeTAIR_e_AGS_CalibrationSts: nonqueued-sender-com-spec{data-element=Value, init-value=CeTAIR_e_AGS_NotCalibrated}, provided-interface=VeTAIR_e_AGS_CalibrationSts
      VeTAIR_b_AGS2_BoostSts: nonqueued-sender-com-spec{data-element=Value, init-value=0}, provided-interface=VeTAIR_b_AGS2_BoostSts
      VeTAIR_b_AGS2_CalibrationActv: nonqueued-sender-com-spec{data-element=Value, init-value=0}, provided-interface=VeTAIR_b_AGS2_CalibrationActv
      VeTAIR_b_AGS2_ErrMechBreak: nonqueued-sender-com-spec{data-element=Value, init-value=0}, provided-interface=VeTAIR_b_AGS2_ErrMechBreak
      VeTAIR_b_AGS2_ErrMechStuck: nonqueued-sender-com-spec{data-element=Value, init-value=0}, provided-interface=VeTAIR_b_AGS2_ErrMechStuck
      VeTAIR_b_AGS2_ErrOverTemp: nonqueued-sender-com-spec{data-element=Value, init-value=0}, provided-interface=VeTAIR_b_AGS2_ErrOverTemp
      VeTAIR_b_AGS2_ErrOverVolt: nonqueued-sender-com-spec{data-element=Value, init-value=0}, provided-interface=VeTAIR_b_AGS2_ErrOverVolt
      VeTAIR_b_AGS2_ErrFdbFA: nonqueued-sender-com-spec{data-element=Value, init-value=0}, provided-interface=VeTAIR_b_AGS2_ErrFdbFA
      VeTAIR_e_AGS2_ErrFdb: nonqueued-sender-com-spec{data-element=Value, init-value=CeTAIR_e_AGS_NO_ERROR}, provided-interface=VeTAIR_e_AGS2_ErrFdb
      VeTAIR_b_AGS2_CurrPosFA: nonqueued-sender-com-spec{data-element=Value, init-value=0}, provided-interface=VeTAIR_b_AGS2_CurrPosFA
      VeTAIR_Pct_AGS2_CurrPos: nonqueued-sender-com-spec{data-element=Value, init-value=0}, provided-interface=VeTAIR_Pct_AGS2_CurrPos
      VeTAIR_b_AGS2_ResErr: nonqueued-sender-com-spec{data-element=Value, init-value=0}, provided-interface=VeTAIR_b_AGS2_ResErr
      VeTAIR_b_AGS2_ErrUnderVolt: nonqueued-sender-com-spec{data-element=Value, init-value=0}, provided-interface=VeTAIR_b_AGS2_ErrUnderVolt
      VeTAIR_e_AGS2_CalibrationSts: nonqueued-sender-com-spec{data-element=Value, init-value=CeTAIR_e_AGS_NotCalibrated}, provided-interface=VeTAIR_e_AGS2_CalibrationSts
      VeTAIR_Pct_ECM_AirflowRequest: nonqueued-sender-com-spec{data-element=Value, init-value=0}, provided-interface=VeTAIR_Pct_ECM_AirflowRequest
      VeTAIR_b_ECM_AirflowRequestFA: nonqueued-sender-com-spec{data-element=Value, init-value=0}, provided-interface=VeTAIR_b_ECM_AirflowRequestFA
      VeTAIR_e_AGS2_CurrPos: nonqueued-sender-com-spec{data-element=Value, init-value=CeFSCR_e_Open100}, provided-interface=VeTAIR_e_AGS2_CurrPos
      VeTAIR_e_AGS_CurrPos: nonqueued-sender-com-spec{data-element=Value, init-value=CeFSCR_e_Open100}, provided-interface=VeTAIR_e_AGS_CurrPos
      VeTAIR_e_AGS_IO_CntrlSt: nonqueued-sender-com-spec{data-element=Value, init-value=CeTAIR_e_Return_Control_to_ECU}, provided-interface=VeTAIR_e_AGS_IO_CntrlSt
      VeTAIR_e_AGS_PstnCmnd: nonqueued-sender-com-spec{data-element=Value, init-value=CeFSCR_e_Open100}, provided-interface=VeTAIR_e_AGS_PstnCmnd
      VeTAIR_b_DVC_AGS_Calibration_Start: nonqueued-sender-com-spec{data-element=Value, init-value=0}, provided-interface=VeTAIR_b_DVC_AGS_Calibration_Start
      VeTAIR_e_AGS2_IO_CntrlSt: nonqueued-sender-com-spec{data-element=Value, init-value=CeTAIR_e_Return_Control_to_ECU}, provided-interface=VeTAIR_e_AGS2_IO_CntrlSt
      VeTAIR_e_AGS2_PstnCmnd: nonqueued-sender-com-spec{data-element=Value, init-value=CeFSCR_e_Open100}, provided-interface=VeTAIR_e_AGS2_PstnCmnd
      VeTAIR_b_DVC_AGS2_Calibration_Start: nonqueued-sender-com-spec{data-element=Value, init-value=0}, provided-interface=VeTAIR_b_DVC_AGS2_Calibration_Start
      VeTAIR_T_OEXV_RefTemp: nonqueued-sender-com-spec{data-element=Value, init-value=0}, provided-interface=VeTAIR_T_OEXV_RefTemp
      VeTAIR_b_OEXV_RefTemp_FA: nonqueued-sender-com-spec{data-element=Value, init-value=0}, provided-interface=VeTAIR_b_OEXV_RefTemp_FA
      VeTAIR_p_OEXV_RefPress: nonqueued-sender-com-spec{data-element=Value, init-value=0}, provided-interface=VeTAIR_p_OEXV_RefPress
      VeTAIR_b_OEXV_RefPress_FA: nonqueued-sender-com-spec{data-element=Value, init-value=0}, provided-interface=VeTAIR_b_OEXV_RefPress_FA
      VeTAIR_e_EEXV_IO_CntrlSt: nonqueued-sender-com-spec{data-element=Value, init-value=CeTAIR_e_Return_Control_to_ECU}, provided-interface=VeTAIR_e_EEXV_IO_CntrlSt
      VeTAIR_Pct_EEXV_Cmd: nonqueued-sender-com-spec{data-element=Value, init-value=0}, provided-interface=VeTAIR_Pct_EEXV_Cmd
      VeTAIR_b_DVC_EEXV_Calibration_Start: nonqueued-sender-com-spec{data-element=Value, init-value=0}, provided-interface=VeTAIR_b_DVC_EEXV_Calibration_Start
      VeTAIR_e_OEXV_IO_CntrlSt: nonqueued-sender-com-spec{data-element=Value, init-value=CeTAIR_e_Return_Control_to_ECU}, provided-interface=VeTAIR_e_OEXV_IO_CntrlSt
      VeTAIR_Pct_OEXV_Cmd: nonqueued-sender-com-spec{data-element=Value, init-value=0}, provided-interface=VeTAIR_Pct_OEXV_Cmd
      VeTAIR_b_DVC_OEXV_Calibration_Start: nonqueued-sender-com-spec{data-element=Value, init-value=0}, provided-interface=VeTAIR_b_DVC_OEXV_Calibration_Start
      VeTAIR_Pct_HTRBV_ActuatorPosTrgt: nonqueued-sender-com-spec{data-element=Value, init-value=0}, provided-interface=VeTAIR_Pct_HTRBV_ActuatorPosTrgt
      VeTAIR_b_HTRBV_ActuatorPosAct_FA: nonqueued-sender-com-spec{data-element=Value, init-value=0}, provided-interface=VeTAIR_b_HTRBV_ActuatorPosAct_FA
      VeTAIR_T_HTRBV_EcuTemp: nonqueued-sender-com-spec{data-element=Value, init-value=0}, provided-interface=VeTAIR_T_HTRBV_EcuTemp
      VeTAIR_U_HTRBV_EcuVoltage: nonqueued-sender-com-spec{data-element=Value, init-value=0}, provided-interface=VeTAIR_U_HTRBV_EcuVoltage
      VeTAIR_b_HTRBV_ResponseError: nonqueued-sender-com-spec{data-element=Value, init-value=0}, provided-interface=VeTAIR_b_HTRBV_ResponseError
      VeTAIR_Pct_HTRBV_ActuatorPosAct: nonqueued-sender-com-spec{data-element=Value, init-value=0}, provided-interface=VeTAIR_Pct_HTRBV_ActuatorPosAct
      VeTAIR_b_HTRBV_SelfCalReq: nonqueued-sender-com-spec{data-element=Value, init-value=0}, provided-interface=VeTAIR_b_HTRBV_SelfCalReq
      VeTAIR_e_HTRBV_Err_Ecu: nonqueued-sender-com-spec{data-element=Value, init-value=CeTAIR_e_NoEcuError}, provided-interface=VeTAIR_e_HTRBV_Err_Ecu
      VeTAIR_e_HTRBV_Err_Motor: nonqueued-sender-com-spec{data-element=Value, init-value=CeTAIR_e_NoMotorError}, provided-interface=VeTAIR_e_HTRBV_Err_Motor
      VeTAIR_e_HTRBV_Err_Voltage: nonqueued-sender-com-spec{data-element=Value, init-value=CeTAIR_e_NoVoltError}, provided-interface=VeTAIR_e_HTRBV_Err_Voltage
      VeTAIR_e_HTRBV_ErrLinCom: nonqueued-sender-com-spec{data-element=Value, init-value=CeTAIR_e_LINComNoErrors}, provided-interface=VeTAIR_e_HTRBV_ErrLinCom
      VeTAIR_e_HTRBV_ErrPosition: nonqueued-sender-com-spec{data-element=Value, init-value=CeTAIR_e_NoPosError}, provided-interface=VeTAIR_e_HTRBV_ErrPosition
      VeTAIR_e_HTRBV_SystemState: nonqueued-sender-com-spec{data-element=Value, init-value=CeTAIR_e_Normal}, provided-interface=VeTAIR_e_HTRBV_SystemState
      VeTAIR_Pct_CPV2_PstnAct: nonqueued-sender-com-spec{data-element=Value, init-value=0}, provided-interface=VeTAIR_Pct_CPV2_PstnAct
      VeTAIR_b_CPV2_PstnAct_FA: nonqueued-sender-com-spec{data-element=Value, init-value=0}, provided-interface=VeTAIR_b_CPV2_PstnAct_FA
      VeTAIR_b_CPV2_OvrVltg: nonqueued-sender-com-spec{data-element=Value, init-value=0}, provided-interface=VeTAIR_b_CPV2_OvrVltg
      VeTAIR_b_CPV2_UndrVltg: nonqueued-sender-com-spec{data-element=Value, init-value=0}, provided-interface=VeTAIR_b_CPV2_UndrVltg
      VeTAIR_b_CPV2_ThrmlWrng: nonqueued-sender-com-spec{data-element=Value, init-value=0}, provided-interface=VeTAIR_b_CPV2_ThrmlWrng
      VeTAIR_b_CPV2_OpnLd: nonqueued-sender-com-spec{data-element=Value, init-value=0}, provided-interface=VeTAIR_b_CPV2_OpnLd
      VeTAIR_b_CPV2_OvrCrnt: nonqueued-sender-com-spec{data-element=Value, init-value=0}, provided-interface=VeTAIR_b_CPV2_OvrCrnt
      VeTAIR_b_CPV2_MechBrk: nonqueued-sender-com-spec{data-element=Value, init-value=0}, provided-interface=VeTAIR_b_CPV2_MechBrk
      VeTAIR_b_CPV2_BlckPnt: nonqueued-sender-com-spec{data-element=Value, init-value=0}, provided-interface=VeTAIR_b_CPV2_BlckPnt
      VeTAIR_b_CPV2_Err_SNA: nonqueued-sender-com-spec{data-element=Value, init-value=0}, provided-interface=VeTAIR_b_CPV2_Err_SNA
      VeTAIR_U_CPV2_MtrVltg: nonqueued-sender-com-spec{data-element=Value, init-value=0}, provided-interface=VeTAIR_U_CPV2_MtrVltg
      VeTAIR_e_CPV2_ErrSts: nonqueued-sender-com-spec{data-element=Value, init-value=CeTAIR_e_CPV_Status_OK}, provided-interface=VeTAIR_e_CPV2_ErrSts
      VeTAIR_b_CPV2_RsErr: nonqueued-sender-com-spec{data-element=Value, init-value=0}, provided-interface=VeTAIR_b_CPV2_RsErr
      VeTAIR_e_CPV2_CalSts: nonqueued-sender-com-spec{data-element=Value, init-value=CeTAIR_e_CPV_Calibration_Complete}, provided-interface=VeTAIR_e_CPV2_CalSts
      VeTAIR_e_RearDefrostSts: nonqueued-sender-com-spec{data-element=Value, init-value=CeTAIR_e_RearDefrostSts_OFF}, provided-interface=VeTAIR_e_RearDefrostSts
      VeTAIR_b_RearDefrostStsFA: nonqueued-sender-com-spec{data-element=Value, init-value=0}, provided-interface=VeTAIR_b_RearDefrostStsFA
      VeTAIR_y_RearCabinFanSts: nonqueued-sender-com-spec{data-element=Value, init-value=0}, provided-interface=VeTAIR_y_RearCabinFanSts
      VeTAIR_b_RearCabinFanStsFA: nonqueued-sender-com-spec{data-element=Value, init-value=0}, provided-interface=VeTAIR_b_RearCabinFanStsFA
      FsftTAIR_I_ACCElecCurr: server-com-spec=FsftTAIR_I_ACCElecCurr, provided-interface=FsftTAIR_I_ACCElecCurr
      FsftTAIR_P_ACCompElec_Pwr: server-com-spec=FsftTAIR_P_ACCompElec_Pwr, provided-interface=FsftTAIR_P_ACCompElec_Pwr
      FsftTAIR_Pct_CPV2_ActlPstn: server-com-spec=FsftTAIR_Pct_CPV2_ActlPstn, provided-interface=FsftTAIR_Pct_CPV2_ActlPstn
      FsftTAIR_Pct_DrvTmpDr_Pos: server-com-spec=FsftTAIR_Pct_DrvTmpDr_Pos, provided-interface=FsftTAIR_Pct_DrvTmpDr_Pos
      FsftTAIR_Pct_ECM_AirflowRequest: server-com-spec=FsftTAIR_Pct_ECM_AirflowRequest, provided-interface=FsftTAIR_Pct_ECM_AirflowRequest
      FsftTAIR_Pct_ECM_RadFanReq: server-com-spec=FsftTAIR_Pct_ECM_RadFanReq, provided-interface=FsftTAIR_Pct_ECM_RadFanReq
      FsftTAIR_Pct_EEXV_PosAct: server-com-spec=FsftTAIR_Pct_EEXV_PosAct, provided-interface=FsftTAIR_Pct_EEXV_PosAct
      FsftTAIR_Pct_EXV_PosAct: server-com-spec=FsftTAIR_Pct_EXV_PosAct, provided-interface=FsftTAIR_Pct_EXV_PosAct
      FsftTAIR_Pct_FrWyVlv_ActlPstn: server-com-spec=FsftTAIR_Pct_FrWyVlv_ActlPstn, provided-interface=FsftTAIR_Pct_FrWyVlv_ActlPstn
      FsftTAIR_Pct_FrtBlwrCmd: server-com-spec=FsftTAIR_Pct_FrtBlwrCmd, provided-interface=FsftTAIR_Pct_FrtBlwrCmd
      FsftTAIR_Pct_HTL_BypsVlv_ActlPstn: server-com-spec=FsftTAIR_Pct_HTL_BypsVlv_ActlPstn, provided-interface=FsftTAIR_Pct_HTL_BypsVlv_ActlPstn
      FsftTAIR_Pct_HTRBV_ActuatorPosAct: server-com-spec=FsftTAIR_Pct_HTRBV_ActuatorPosAct, provided-interface=FsftTAIR_Pct_HTRBV_ActuatorPosAct
      FsftTAIR_Pct_LTR_BypsVlv_ActlPstn: server-com-spec=FsftTAIR_Pct_LTR_BypsVlv_ActlPstn, provided-interface=FsftTAIR_Pct_LTR_BypsVlv_ActlPstn
      FsftTAIR_Pct_OEXV_PosAct: server-com-spec=FsftTAIR_Pct_OEXV_PosAct, provided-interface=FsftTAIR_Pct_OEXV_PosAct
      FsftTAIR_Pct_PasTmpDr_Pos: server-com-spec=FsftTAIR_Pct_PasTmpDr_Pos, provided-interface=FsftTAIR_Pct_PasTmpDr_Pos
      FsftTAIR_Pct_RrBlwrCmd: server-com-spec=FsftTAIR_Pct_RrBlwrCmd, provided-interface=FsftTAIR_Pct_RrBlwrCmd
      FsftTAIR_Pct_RrTmpDr_Cmd: server-com-spec=FsftTAIR_Pct_RrTmpDr_Cmd, provided-interface=FsftTAIR_Pct_RrTmpDr_Cmd
      FsftTAIR_T_CompBoardTemp: server-com-spec=FsftTAIR_T_CompBoardTemp, provided-interface=FsftTAIR_T_CompBoardTemp
      FsftTAIR_T_CompIGBTTemp: server-com-spec=FsftTAIR_T_CompIGBTTemp, provided-interface=FsftTAIR_T_CompIGBTTemp
      FsftTAIR_T_EEXV_RefTemp: server-com-spec=FsftTAIR_T_EEXV_RefTemp, provided-interface=FsftTAIR_T_EEXV_RefTemp
      FsftTAIR_T_EXV_BoardTemp: server-com-spec=FsftTAIR_T_EXV_BoardTemp, provided-interface=FsftTAIR_T_EXV_BoardTemp
      FsftTAIR_T_EXV_RefTemp: server-com-spec=FsftTAIR_T_EXV_RefTemp, provided-interface=FsftTAIR_T_EXV_RefTemp
      FsftTAIR_T_FtEvapTmp: server-com-spec=FsftTAIR_T_FtEvapTmp, provided-interface=FsftTAIR_T_FtEvapTmp
      FsftTAIR_T_FtEvapTmp_P1C: server-com-spec=FsftTAIR_T_FtEvapTmp_P1C, provided-interface=FsftTAIR_T_FtEvapTmp_P1C
      FsftTAIR_T_FtEvapTmp_Tgt: server-com-spec=FsftTAIR_T_FtEvapTmp_Tgt, provided-interface=FsftTAIR_T_FtEvapTmp_Tgt
      FsftTAIR_T_HtrCoreTmp_Tgt: server-com-spec=FsftTAIR_T_HtrCoreTmp_Tgt, provided-interface=FsftTAIR_T_HtrCoreTmp_Tgt
      FsftTAIR_T_OEXV_RefTemp: server-com-spec=FsftTAIR_T_OEXV_RefTemp, provided-interface=FsftTAIR_T_OEXV_RefTemp
      FsftTAIR_T_VhIntTmp: server-com-spec=FsftTAIR_T_VhIntTmp, provided-interface=FsftTAIR_T_VhIntTmp
      FsftTAIR_U_CompHVInput: server-com-spec=FsftTAIR_U_CompHVInput, provided-interface=FsftTAIR_U_CompHVInput
      FsftTAIR_U_EXV_SupplyVolt: server-com-spec=FsftTAIR_U_EXV_SupplyVolt, provided-interface=FsftTAIR_U_EXV_SupplyVolt
      FsftTAIR_U_FrWyVlv_MtrVltg: server-com-spec=FsftTAIR_U_FrWyVlv_MtrVltg, provided-interface=FsftTAIR_U_FrWyVlv_MtrVltg
      FsftTAIR_U_HTL_BypsVlv_MtrVltg: server-com-spec=FsftTAIR_U_HTL_BypsVlv_MtrVltg, provided-interface=FsftTAIR_U_HTL_BypsVlv_MtrVltg
      FsftTAIR_U_LTR_BypsVlv_MtrVltg: server-com-spec=FsftTAIR_U_LTR_BypsVlv_MtrVltg, provided-interface=FsftTAIR_U_LTR_BypsVlv_MtrVltg
      FsftTAIR_b_AGS2_CurrPos: server-com-spec=FsftTAIR_b_AGS2_CurrPos, provided-interface=FsftTAIR_b_AGS2_CurrPos
      FsftTAIR_b_AGS_CurrPos: server-com-spec=FsftTAIR_b_AGS_CurrPos, provided-interface=FsftTAIR_b_AGS_CurrPos
      FsftTAIR_b_EBL_Stat: server-com-spec=FsftTAIR_b_EBL_Stat, provided-interface=FsftTAIR_b_EBL_Stat
      FsftTAIR_b_ECM_AC_ClutchSts: server-com-spec=FsftTAIR_b_ECM_AC_ClutchSts, provided-interface=FsftTAIR_b_ECM_AC_ClutchSts
      FsftTAIR_b_ECVD_HVACCabinReq: server-com-spec=FsftTAIR_b_ECVD_HVACCabinReq, provided-interface=FsftTAIR_b_ECVD_HVACCabinReq
      FsftTAIR_b_ECVD_HVACCurrentAct: server-com-spec=FsftTAIR_b_ECVD_HVACCurrentAct, provided-interface=FsftTAIR_b_ECVD_HVACCurrentAct
      FsftTAIR_b_HghRfrgtPresFailSts: server-com-spec=FsftTAIR_b_HghRfrgtPresFailSts, provided-interface=FsftTAIR_b_HghRfrgtPresFailSts
      FsftTAIR_b_RearCabinFanSts: server-com-spec=FsftTAIR_b_RearCabinFanSts, provided-interface=FsftTAIR_b_RearCabinFanSts
      FsftTAIR_e_AGS2_ErrFdb: server-com-spec=FsftTAIR_e_AGS2_ErrFdb, provided-interface=FsftTAIR_e_AGS2_ErrFdb
      FsftTAIR_e_AGS_ErrFdb: server-com-spec=FsftTAIR_e_AGS_ErrFdb, provided-interface=FsftTAIR_e_AGS_ErrFdb
      FsftTAIR_e_CompFltStat: server-com-spec=FsftTAIR_e_CompFltStat, provided-interface=FsftTAIR_e_CompFltStat
      FsftTAIR_e_CompStat: server-com-spec=FsftTAIR_e_CompStat, provided-interface=FsftTAIR_e_CompStat
      FsftTAIR_e_EXV_CalStat: server-com-spec=FsftTAIR_e_EXV_CalStat, provided-interface=FsftTAIR_e_EXV_CalStat
      FsftTAIR_e_EXV_Err: server-com-spec=FsftTAIR_e_EXV_Err, provided-interface=FsftTAIR_e_EXV_Err
      FsftTAIR_e_EXV_Sts: server-com-spec=FsftTAIR_e_EXV_Sts, provided-interface=FsftTAIR_e_EXV_Sts
      FsftTAIR_e_FrWyVlv_CalSts: server-com-spec=FsftTAIR_e_FrWyVlv_CalSts, provided-interface=FsftTAIR_e_FrWyVlv_CalSts
      FsftTAIR_e_FrWyVlv_ErrSts: server-com-spec=FsftTAIR_e_FrWyVlv_ErrSts, provided-interface=FsftTAIR_e_FrWyVlv_ErrSts
      FsftTAIR_e_HTL_BypsVlv_CalSts: server-com-spec=FsftTAIR_e_HTL_BypsVlv_CalSts, provided-interface=FsftTAIR_e_HTL_BypsVlv_CalSts
      FsftTAIR_e_HTL_BypsVlv_ErrSts: server-com-spec=FsftTAIR_e_HTL_BypsVlv_ErrSts, provided-interface=FsftTAIR_e_HTL_BypsVlv_ErrSts
      FsftTAIR_e_LTR_BypsVlv_CalSts: server-com-spec=FsftTAIR_e_LTR_BypsVlv_CalSts, provided-interface=FsftTAIR_e_LTR_BypsVlv_CalSts
      FsftTAIR_e_LTR_BypsVlv_ErrSts: server-com-spec=FsftTAIR_e_LTR_BypsVlv_ErrSts, provided-interface=FsftTAIR_e_LTR_BypsVlv_ErrSts
      FsftTAIR_kp_EXV_RefPress: server-com-spec=FsftTAIR_kp_EXV_RefPress, provided-interface=FsftTAIR_kp_EXV_RefPress
      FsftTAIR_n_CompSpdFdb: server-com-spec=FsftTAIR_n_CompSpdFdb, provided-interface=FsftTAIR_n_CompSpdFdb
      FsftTAIR_p_EEXV_RefPress: server-com-spec=FsftTAIR_p_EEXV_RefPress, provided-interface=FsftTAIR_p_EEXV_RefPress
      FsftTAIR_p_OEXV_RefPress: server-com-spec=FsftTAIR_p_OEXV_RefPress, provided-interface=FsftTAIR_p_OEXV_RefPress
      FsftTAIR_y_CPV2_ErrMsgs: server-com-spec=FsftTAIR_y_CPV2_ErrMsgs, provided-interface=FsftTAIR_y_CPV2_ErrMsgs
      FsftTAIR_y_FrWyVlv_ErrMsgs: server-com-spec=FsftTAIR_y_FrWyVlv_ErrMsgs, provided-interface=FsftTAIR_y_FrWyVlv_ErrMsgs
      FsftTAIR_y_HTL_BypsVlv_ErrMsgs: server-com-spec=FsftTAIR_y_HTL_BypsVlv_ErrMsgs, provided-interface=FsftTAIR_y_HTL_BypsVlv_ErrMsgs
      FsftTAIR_y_LTR_BypsVlv_ErrMsgs: server-com-spec=FsftTAIR_y_LTR_BypsVlv_ErrMsgs, provided-interface=FsftTAIR_y_LTR_BypsVlv_ErrMsgs
      PokeTAIF_DVC_HTempCbnVlv: server-com-spec{operation=PokeTAIF_DVC_HTempCbnVlv, queue-length=1}, provided-interface=PokeTAIF_DVC_HTempCbnVlv
      PokeTAIF_DVC_LT_Shtoff_VlvCmd: server-com-spec{operation=PokeTAIF_DVC_LT_Shtoff_VlvCmd, queue-length=1}, provided-interface=PokeTAIF_DVC_LT_Shtoff_VlvCmd
      PokeTAIF_e_DVC_HTCV_Calibration_Start: server-com-spec{operation=PokeTAIF_e_DVC_HTCV_Calibration_Start, queue-length=1}, provided-interface=PokeTAIF_e_DVC_HTCV_Calibration_Start
      PokeTAIR_I_ACCElecCurr: server-com-spec{operation=PokeTAIR_I_ACCElecCurr, queue-length=1}, provided-interface=PokeTAIR_I_ACCElecCurr
      PokeTAIR_I_ECVD_HVACCabinReq: server-com-spec{operation=PokeTAIR_I_ECVD_HVACCabinReq, queue-length=1}, provided-interface=PokeTAIR_I_ECVD_HVACCabinReq
      PokeTAIR_I_ECVD_HVACCurrentAct: server-com-spec{operation=PokeTAIR_I_ECVD_HVACCurrentAct, queue-length=1}, provided-interface=PokeTAIR_I_ECVD_HVACCurrentAct
      PokeTAIR_P_ACCompElec_Pwr: server-com-spec{operation=PokeTAIR_P_ACCompElec_Pwr, queue-length=1}, provided-interface=PokeTAIR_P_ACCompElec_Pwr
      PokeTAIR_Pct_AGS2_CurrPos_CAN: server-com-spec{operation=PokeTAIR_Pct_AGS2_CurrPos_CAN, queue-length=1}, provided-interface=PokeTAIR_Pct_AGS2_CurrPos_CAN
      PokeTAIR_Pct_AGS_CurrPos_CAN: server-com-spec{operation=PokeTAIR_Pct_AGS_CurrPos_CAN, queue-length=1}, provided-interface=PokeTAIR_Pct_AGS_CurrPos_CAN
      PokeTAIR_Pct_CPV2_ActlPstn: server-com-spec{operation=PokeTAIR_Pct_CPV2_ActlPstn, queue-length=1}, provided-interface=PokeTAIR_Pct_CPV2_ActlPstn
      PokeTAIR_Pct_DrvTmpDr_Pos: server-com-spec{operation=PokeTAIR_Pct_DrvTmpDr_Pos, queue-length=1}, provided-interface=PokeTAIR_Pct_DrvTmpDr_Pos
      PokeTAIR_Pct_ECM_AirflowRequest: server-com-spec{operation=PokeTAIR_Pct_ECM_AirflowRequest, queue-length=1}, provided-interface=PokeTAIR_Pct_ECM_AirflowRequest
      PokeTAIR_Pct_ECM_RadFanReq: server-com-spec{operation=PokeTAIR_Pct_ECM_RadFanReq, queue-length=1}, provided-interface=PokeTAIR_Pct_ECM_RadFanReq
      PokeTAIR_Pct_EEXV_PosAct: server-com-spec{operation=PokeTAIR_Pct_EEXV_PosAct, queue-length=1}, provided-interface=PokeTAIR_Pct_EEXV_PosAct
      PokeTAIR_Pct_EXV_PosAct: server-com-spec{operation=PokeTAIR_Pct_EXV_PosAct, queue-length=1}, provided-interface=PokeTAIR_Pct_EXV_PosAct
      PokeTAIR_Pct_FrWyVlv_ActlPstn: server-com-spec{operation=PokeTAIR_Pct_FrWyVlv_ActlPstn, queue-length=1}, provided-interface=PokeTAIR_Pct_FrWyVlv_ActlPstn
      PokeTAIR_Pct_FrtBlwrCmd: server-com-spec{operation=PokeTAIR_Pct_FrtBlwrCmd, queue-length=1}, provided-interface=PokeTAIR_Pct_FrtBlwrCmd
      PokeTAIR_Pct_HTL_BypsVlv_ActlPstn: server-com-spec{operation=PokeTAIR_Pct_HTL_BypsVlv_ActlPstn, queue-length=1}, provided-interface=PokeTAIR_Pct_HTL_BypsVlv_ActlPstn
      PokeTAIR_Pct_HTRBV_ActuatorPosAct: server-com-spec{operation=PokeTAIR_Pct_HTRBV_ActuatorPosAct, queue-length=1}, provided-interface=PokeTAIR_Pct_HTRBV_ActuatorPosAct
      PokeTAIR_Pct_HTRBV_ActuatorPosTrgt: server-com-spec{operation=PokeTAIR_Pct_HTRBV_ActuatorPosTrgt, queue-length=1}, provided-interface=PokeTAIR_Pct_HTRBV_ActuatorPosTrgt
      PokeTAIR_Pct_LTR_BypsVlv_ActlPstn: server-com-spec{operation=PokeTAIR_Pct_LTR_BypsVlv_ActlPstn, queue-length=1}, provided-interface=PokeTAIR_Pct_LTR_BypsVlv_ActlPstn
      PokeTAIR_Pct_OEXV_PosAct: server-com-spec{operation=PokeTAIR_Pct_OEXV_PosAct, queue-length=1}, provided-interface=PokeTAIR_Pct_OEXV_PosAct
      PokeTAIR_Pct_PasTmpDr_Pos: server-com-spec{operation=PokeTAIR_Pct_PasTmpDr_Pos, queue-length=1}, provided-interface=PokeTAIR_Pct_PasTmpDr_Pos
      PokeTAIR_Pct_RrBlwrCmd: server-com-spec{operation=PokeTAIR_Pct_RrBlwrCmd, queue-length=1}, provided-interface=PokeTAIR_Pct_RrBlwrCmd
      PokeTAIR_Pct_RrTmpDr_Cmd: server-com-spec{operation=PokeTAIR_Pct_RrTmpDr_Cmd, queue-length=1}, provided-interface=PokeTAIR_Pct_RrTmpDr_Cmd
      PokeTAIR_T_CompBoardTemp: server-com-spec{operation=PokeTAIR_T_CompBoardTemp, queue-length=1}, provided-interface=PokeTAIR_T_CompBoardTemp
      PokeTAIR_T_CompIGBTTemp: server-com-spec{operation=PokeTAIR_T_CompIGBTTemp, queue-length=1}, provided-interface=PokeTAIR_T_CompIGBTTemp
      PokeTAIR_T_EEXV_BoardTemp: server-com-spec{operation=PokeTAIR_T_EEXV_BoardTemp, queue-length=1}, provided-interface=PokeTAIR_T_EEXV_BoardTemp
      PokeTAIR_T_EEXV_RefTemp: server-com-spec{operation=PokeTAIR_T_EEXV_RefTemp, queue-length=1}, provided-interface=PokeTAIR_T_EEXV_RefTemp
      PokeTAIR_T_EXV_BoardTemp: server-com-spec{operation=PokeTAIR_T_EXV_BoardTemp, queue-length=1}, provided-interface=PokeTAIR_T_EXV_BoardTemp
      PokeTAIR_T_EXV_RefTemp: server-com-spec{operation=PokeTAIR_T_EXV_RefTemp, queue-length=1}, provided-interface=PokeTAIR_T_EXV_RefTemp
      PokeTAIR_T_FtEvapTmp: server-com-spec{operation=PokeTAIR_T_FtEvapTmp, queue-length=1}, provided-interface=PokeTAIR_T_FtEvapTmp
      PokeTAIR_T_FtEvapTmp_P1C: server-com-spec{operation=PokeTAIR_T_FtEvapTmp_P1C, queue-length=1}, provided-interface=PokeTAIR_T_FtEvapTmp_P1C
      PokeTAIR_T_FtEvapTmp_Tgt: server-com-spec{operation=PokeTAIR_T_FtEvapTmp_Tgt, queue-length=1}, provided-interface=PokeTAIR_T_FtEvapTmp_Tgt
      PokeTAIR_T_HTRBV_EcuTemp: server-com-spec{operation=PokeTAIR_T_HTRBV_EcuTemp, queue-length=1}, provided-interface=PokeTAIR_T_HTRBV_EcuTemp
      PokeTAIR_T_HtrCoreTmp_Tgt: server-com-spec{operation=PokeTAIR_T_HtrCoreTmp_Tgt, queue-length=1}, provided-interface=PokeTAIR_T_HtrCoreTmp_Tgt
      PokeTAIR_T_OEXV_BoardTemp: server-com-spec{operation=PokeTAIR_T_OEXV_BoardTemp, queue-length=1}, provided-interface=PokeTAIR_T_OEXV_BoardTemp
      PokeTAIR_T_OEXV_RefTemp: server-com-spec{operation=PokeTAIR_T_OEXV_RefTemp, queue-length=1}, provided-interface=PokeTAIR_T_OEXV_RefTemp
      PokeTAIR_T_VhIntTmp: server-com-spec{operation=PokeTAIR_T_VhIntTmp, queue-length=1}, provided-interface=PokeTAIR_T_VhIntTmp
      PokeTAIR_U_CPV2_MtrVltg: server-com-spec{operation=PokeTAIR_U_CPV2_MtrVltg, queue-length=1}, provided-interface=PokeTAIR_U_CPV2_MtrVltg
      PokeTAIR_U_CompHVInput: server-com-spec{operation=PokeTAIR_U_CompHVInput, queue-length=1}, provided-interface=PokeTAIR_U_CompHVInput
      PokeTAIR_U_EEXV_SupplyVolt: server-com-spec{operation=PokeTAIR_U_EEXV_SupplyVolt, queue-length=1}, provided-interface=PokeTAIR_U_EEXV_SupplyVolt
      PokeTAIR_U_EXV_SupplyVolt: server-com-spec{operation=PokeTAIR_U_EXV_SupplyVolt, queue-length=1}, provided-interface=PokeTAIR_U_EXV_SupplyVolt
      PokeTAIR_U_FrWyVlv_MtrVltg: server-com-spec{operation=PokeTAIR_U_FrWyVlv_MtrVltg, queue-length=1}, provided-interface=PokeTAIR_U_FrWyVlv_MtrVltg
      PokeTAIR_U_HTL_BypsVlv_MtrVltg: server-com-spec{operation=PokeTAIR_U_HTL_BypsVlv_MtrVltg, queue-length=1}, provided-interface=PokeTAIR_U_HTL_BypsVlv_MtrVltg
      PokeTAIR_U_HTRBV_EcuVoltage: server-com-spec{operation=PokeTAIR_U_HTRBV_EcuVoltage, queue-length=1}, provided-interface=PokeTAIR_U_HTRBV_EcuVoltage
      PokeTAIR_U_HT_CabVlvSts: server-com-spec{operation=PokeTAIR_U_HT_CabVlvSts, queue-length=1}, provided-interface=PokeTAIR_U_HT_CabVlvSts
      PokeTAIR_U_LTR_BypsVlv_MtrVltg: server-com-spec{operation=PokeTAIR_U_LTR_BypsVlv_MtrVltg, queue-length=1}, provided-interface=PokeTAIR_U_LTR_BypsVlv_MtrVltg
      PokeTAIR_U_OEXV_SupplyVolt: server-com-spec{operation=PokeTAIR_U_OEXV_SupplyVolt, queue-length=1}, provided-interface=PokeTAIR_U_OEXV_SupplyVolt
      PokeTAIR_b_ACCompReq: server-com-spec{operation=PokeTAIR_b_ACCompReq, queue-length=1}, provided-interface=PokeTAIR_b_ACCompReq
      PokeTAIR_b_AGS2_BoostSts: server-com-spec{operation=PokeTAIR_b_AGS2_BoostSts, queue-length=1}, provided-interface=PokeTAIR_b_AGS2_BoostSts
      PokeTAIR_b_AGS2_CalibrationActv: server-com-spec{operation=PokeTAIR_b_AGS2_CalibrationActv, queue-length=1}, provided-interface=PokeTAIR_b_AGS2_CalibrationActv
      PokeTAIR_b_AGS2_ErrMechBreak: server-com-spec{operation=PokeTAIR_b_AGS2_ErrMechBreak, queue-length=1}, provided-interface=PokeTAIR_b_AGS2_ErrMechBreak
      PokeTAIR_b_AGS2_ErrMechStuck: server-com-spec{operation=PokeTAIR_b_AGS2_ErrMechStuck, queue-length=1}, provided-interface=PokeTAIR_b_AGS2_ErrMechStuck
      PokeTAIR_b_AGS2_ErrOverTemp: server-com-spec{operation=PokeTAIR_b_AGS2_ErrOverTemp, queue-length=1}, provided-interface=PokeTAIR_b_AGS2_ErrOverTemp
      PokeTAIR_b_AGS2_ErrOverVolt: server-com-spec{operation=PokeTAIR_b_AGS2_ErrOverVolt, queue-length=1}, provided-interface=PokeTAIR_b_AGS2_ErrOverVolt
      PokeTAIR_b_AGS2_ErrUnderVolt: server-com-spec{operation=PokeTAIR_b_AGS2_ErrUnderVolt, queue-length=1}, provided-interface=PokeTAIR_b_AGS2_ErrUnderVolt
      PokeTAIR_b_AGS2_ResErr: server-com-spec{operation=PokeTAIR_b_AGS2_ResErr, queue-length=1}, provided-interface=PokeTAIR_b_AGS2_ResErr
      PokeTAIR_b_AGS_BoostSts: server-com-spec{operation=PokeTAIR_b_AGS_BoostSts, queue-length=1}, provided-interface=PokeTAIR_b_AGS_BoostSts
      PokeTAIR_b_AGS_CalibrationActv: server-com-spec{operation=PokeTAIR_b_AGS_CalibrationActv, queue-length=1}, provided-interface=PokeTAIR_b_AGS_CalibrationActv
      PokeTAIR_b_AGS_ErrMechBreak: server-com-spec{operation=PokeTAIR_b_AGS_ErrMechBreak, queue-length=1}, provided-interface=PokeTAIR_b_AGS_ErrMechBreak
      PokeTAIR_b_AGS_ErrMechStuck: server-com-spec{operation=PokeTAIR_b_AGS_ErrMechStuck, queue-length=1}, provided-interface=PokeTAIR_b_AGS_ErrMechStuck
      PokeTAIR_b_AGS_ErrOverTemp: server-com-spec{operation=PokeTAIR_b_AGS_ErrOverTemp, queue-length=1}, provided-interface=PokeTAIR_b_AGS_ErrOverTemp
      PokeTAIR_b_AGS_ErrOverVolt: server-com-spec{operation=PokeTAIR_b_AGS_ErrOverVolt, queue-length=1}, provided-interface=PokeTAIR_b_AGS_ErrOverVolt
      PokeTAIR_b_AGS_ErrUnderVolt: server-com-spec{operation=PokeTAIR_b_AGS_ErrUnderVolt, queue-length=1}, provided-interface=PokeTAIR_b_AGS_ErrUnderVolt
      PokeTAIR_b_AGS_ResErr: server-com-spec{operation=PokeTAIR_b_AGS_ResErr, queue-length=1}, provided-interface=PokeTAIR_b_AGS_ResErr
      PokeTAIR_b_CPV2_RsErr: server-com-spec{operation=PokeTAIR_b_CPV2_RsErr, queue-length=1}, provided-interface=PokeTAIR_b_CPV2_RsErr
      PokeTAIR_b_CompSpdIncrReq: server-com-spec{operation=PokeTAIR_b_CompSpdIncrReq, queue-length=1}, provided-interface=PokeTAIR_b_CompSpdIncrReq
      PokeTAIR_b_EEXV_CalRq: server-com-spec{operation=PokeTAIR_b_EEXV_CalRq, queue-length=1}, provided-interface=PokeTAIR_b_EEXV_CalRq
      PokeTAIR_b_EEXV_RspErr: server-com-spec{operation=PokeTAIR_b_EEXV_RspErr, queue-length=1}, provided-interface=PokeTAIR_b_EEXV_RspErr
      PokeTAIR_b_EXV_CalRq: server-com-spec{operation=PokeTAIR_b_EXV_CalRq, queue-length=1}, provided-interface=PokeTAIR_b_EXV_CalRq
      PokeTAIR_b_EXV_RspErr: server-com-spec{operation=PokeTAIR_b_EXV_RspErr, queue-length=1}, provided-interface=PokeTAIR_b_EXV_RspErr
      PokeTAIR_b_FrWyVlv_RsErr: server-com-spec{operation=PokeTAIR_b_FrWyVlv_RsErr, queue-length=1}, provided-interface=PokeTAIR_b_FrWyVlv_RsErr
      PokeTAIR_b_HTL_BypsVlv_RsErr: server-com-spec{operation=PokeTAIR_b_HTL_BypsVlv_RsErr, queue-length=1}, provided-interface=PokeTAIR_b_HTL_BypsVlv_RsErr
      PokeTAIR_b_HTRBV_ResponseError: server-com-spec{operation=PokeTAIR_b_HTRBV_ResponseError, queue-length=1}, provided-interface=PokeTAIR_b_HTRBV_ResponseError
      PokeTAIR_b_HTRBV_SelfCalReq: server-com-spec{operation=PokeTAIR_b_HTRBV_SelfCalReq, queue-length=1}, provided-interface=PokeTAIR_b_HTRBV_SelfCalReq
      PokeTAIR_b_HghRfrgtPresFailSts: server-com-spec{operation=PokeTAIR_b_HghRfrgtPresFailSts, queue-length=1}, provided-interface=PokeTAIR_b_HghRfrgtPresFailSts
      PokeTAIR_b_LTR_BypsVlv_RsErr: server-com-spec{operation=PokeTAIR_b_LTR_BypsVlv_RsErr, queue-length=1}, provided-interface=PokeTAIR_b_LTR_BypsVlv_RsErr
      PokeTAIR_b_OEXV_CalRq: server-com-spec{operation=PokeTAIR_b_OEXV_CalRq, queue-length=1}, provided-interface=PokeTAIR_b_OEXV_CalRq
      PokeTAIR_b_OEXV_RspErr: server-com-spec{operation=PokeTAIR_b_OEXV_RspErr, queue-length=1}, provided-interface=PokeTAIR_b_OEXV_RspErr
      PokeTAIR_b_RespErr_EAC: server-com-spec{operation=PokeTAIR_b_RespErr_EAC, queue-length=1}, provided-interface=PokeTAIR_b_RespErr_EAC
      PokeTAIR_b_WinshldDfrst: server-com-spec{operation=PokeTAIR_b_WinshldDfrst, queue-length=1}, provided-interface=PokeTAIR_b_WinshldDfrst
      PokeTAIR_e_AGS2_CalibrationSts: server-com-spec{operation=PokeTAIR_e_AGS2_CalibrationSts, queue-length=1}, provided-interface=PokeTAIR_e_AGS2_CalibrationSts
      PokeTAIR_e_AGS2_CurrPos_LIN: server-com-spec{operation=PokeTAIR_e_AGS2_CurrPos_LIN, queue-length=1}, provided-interface=PokeTAIR_e_AGS2_CurrPos_LIN
      PokeTAIR_e_AGS2_ErrFdb: server-com-spec{operation=PokeTAIR_e_AGS2_ErrFdb, queue-length=1}, provided-interface=PokeTAIR_e_AGS2_ErrFdb
      PokeTAIR_e_AGS_CalibrationSts: server-com-spec{operation=PokeTAIR_e_AGS_CalibrationSts, queue-length=1}, provided-interface=PokeTAIR_e_AGS_CalibrationSts
      PokeTAIR_e_AGS_CurrPos_LIN: server-com-spec{operation=PokeTAIR_e_AGS_CurrPos_LIN, queue-length=1}, provided-interface=PokeTAIR_e_AGS_CurrPos_LIN
      PokeTAIR_e_AGS_ErrFdb: server-com-spec{operation=PokeTAIR_e_AGS_ErrFdb, queue-length=1}, provided-interface=PokeTAIR_e_AGS_ErrFdb
      PokeTAIR_e_CPV2_CalSts: server-com-spec{operation=PokeTAIR_e_CPV2_CalSts, queue-length=1}, provided-interface=PokeTAIR_e_CPV2_CalSts
      PokeTAIR_e_CPV2_ErrSts: server-com-spec{operation=PokeTAIR_e_CPV2_ErrSts, queue-length=1}, provided-interface=PokeTAIR_e_CPV2_ErrSts
      PokeTAIR_e_CompFltStat: server-com-spec{operation=PokeTAIR_e_CompFltStat, queue-length=1}, provided-interface=PokeTAIR_e_CompFltStat
      PokeTAIR_e_CompStat: server-com-spec{operation=PokeTAIR_e_CompStat, queue-length=1}, provided-interface=PokeTAIR_e_CompStat
      PokeTAIR_e_ECM_AC_ClutchSts: server-com-spec{operation=PokeTAIR_e_ECM_AC_ClutchSts, queue-length=1}, provided-interface=PokeTAIR_e_ECM_AC_ClutchSts
      PokeTAIR_e_EEXV_CalStat: server-com-spec{operation=PokeTAIR_e_EEXV_CalStat, queue-length=1}, provided-interface=PokeTAIR_e_EEXV_CalStat
      PokeTAIR_e_EEXV_Err: server-com-spec{operation=PokeTAIR_e_EEXV_Err, queue-length=1}, provided-interface=PokeTAIR_e_EEXV_Err
      PokeTAIR_e_EEXV_Sts: server-com-spec{operation=PokeTAIR_e_EEXV_Sts, queue-length=1}, provided-interface=PokeTAIR_e_EEXV_Sts
      PokeTAIR_e_EXV_CalStat: server-com-spec{operation=PokeTAIR_e_EXV_CalStat, queue-length=1}, provided-interface=PokeTAIR_e_EXV_CalStat
      PokeTAIR_e_EXV_Err: server-com-spec{operation=PokeTAIR_e_EXV_Err, queue-length=1}, provided-interface=PokeTAIR_e_EXV_Err
      PokeTAIR_e_EXV_Sts: server-com-spec{operation=PokeTAIR_e_EXV_Sts, queue-length=1}, provided-interface=PokeTAIR_e_EXV_Sts
      PokeTAIR_e_FrWyVlv_CalSts: server-com-spec{operation=PokeTAIR_e_FrWyVlv_CalSts, queue-length=1}, provided-interface=PokeTAIR_e_FrWyVlv_CalSts
      PokeTAIR_e_FrWyVlv_ErrSts: server-com-spec{operation=PokeTAIR_e_FrWyVlv_ErrSts, queue-length=1}, provided-interface=PokeTAIR_e_FrWyVlv_ErrSts
      PokeTAIR_e_HTL_BypsVlv_CalSts: server-com-spec{operation=PokeTAIR_e_HTL_BypsVlv_CalSts, queue-length=1}, provided-interface=PokeTAIR_e_HTL_BypsVlv_CalSts
      PokeTAIR_e_HTL_BypsVlv_ErrSts: server-com-spec{operation=PokeTAIR_e_HTL_BypsVlv_ErrSts, queue-length=1}, provided-interface=PokeTAIR_e_HTL_BypsVlv_ErrSts
      PokeTAIR_e_HTRBV_ErrLinCom: server-com-spec{operation=PokeTAIR_e_HTRBV_ErrLinCom, queue-length=1}, provided-interface=PokeTAIR_e_HTRBV_ErrLinCom
      PokeTAIR_e_HTRBV_ErrPosition: server-com-spec{operation=PokeTAIR_e_HTRBV_ErrPosition, queue-length=1}, provided-interface=PokeTAIR_e_HTRBV_ErrPosition
      PokeTAIR_e_HTRBV_Err_Ecu: server-com-spec{operation=PokeTAIR_e_HTRBV_Err_Ecu, queue-length=1}, provided-interface=PokeTAIR_e_HTRBV_Err_Ecu
      PokeTAIR_e_HTRBV_Err_Motor: server-com-spec{operation=PokeTAIR_e_HTRBV_Err_Motor, queue-length=1}, provided-interface=PokeTAIR_e_HTRBV_Err_Motor
      PokeTAIR_e_HTRBV_Err_Voltage: server-com-spec{operation=PokeTAIR_e_HTRBV_Err_Voltage, queue-length=1}, provided-interface=PokeTAIR_e_HTRBV_Err_Voltage
      PokeTAIR_e_HTRBV_SystemState: server-com-spec{operation=PokeTAIR_e_HTRBV_SystemState, queue-length=1}, provided-interface=PokeTAIR_e_HTRBV_SystemState
      PokeTAIR_e_LTR_BypsVlv_CalSts: server-com-spec{operation=PokeTAIR_e_LTR_BypsVlv_CalSts, queue-length=1}, provided-interface=PokeTAIR_e_LTR_BypsVlv_CalSts
      PokeTAIR_e_LTR_BypsVlv_ErrSts: server-com-spec{operation=PokeTAIR_e_LTR_BypsVlv_ErrSts, queue-length=1}, provided-interface=PokeTAIR_e_LTR_BypsVlv_ErrSts
      PokeTAIR_e_OEXV_CalStat: server-com-spec{operation=PokeTAIR_e_OEXV_CalStat, queue-length=1}, provided-interface=PokeTAIR_e_OEXV_CalStat
      PokeTAIR_e_OEXV_Err: server-com-spec{operation=PokeTAIR_e_OEXV_Err, queue-length=1}, provided-interface=PokeTAIR_e_OEXV_Err
      PokeTAIR_e_OEXV_Sts: server-com-spec{operation=PokeTAIR_e_OEXV_Sts, queue-length=1}, provided-interface=PokeTAIR_e_OEXV_Sts
      PokeTAIR_e_RearDefrostSts: server-com-spec{operation=PokeTAIR_e_RearDefrostSts, queue-length=1}, provided-interface=PokeTAIR_e_RearDefrostSts
      PokeTAIR_kp_EXV_RefPress: server-com-spec{operation=PokeTAIR_kp_EXV_RefPress, queue-length=1}, provided-interface=PokeTAIR_kp_EXV_RefPress
      PokeTAIR_n_CompSpdFdb: server-com-spec{operation=PokeTAIR_n_CompSpdFdb, queue-length=1}, provided-interface=PokeTAIR_n_CompSpdFdb
      PokeTAIR_p_EEXV_RefPress: server-com-spec{operation=PokeTAIR_p_EEXV_RefPress, queue-length=1}, provided-interface=PokeTAIR_p_EEXV_RefPress
      PokeTAIR_p_OEXV_RefPress: server-com-spec{operation=PokeTAIR_p_OEXV_RefPress, queue-length=1}, provided-interface=PokeTAIR_p_OEXV_RefPress
      PokeTAIR_y_CPV2_ErrMsgs: server-com-spec{operation=PokeTAIR_y_CPV2_ErrMsgs, queue-length=1}, provided-interface=PokeTAIR_y_CPV2_ErrMsgs
      PokeTAIR_y_FrWyVlv_ErrMsgs: server-com-spec{operation=PokeTAIR_y_FrWyVlv_ErrMsgs, queue-length=1}, provided-interface=PokeTAIR_y_FrWyVlv_ErrMsgs
      PokeTAIR_y_HTL_BypsVlv_ErrMsgs: server-com-spec{operation=PokeTAIR_y_HTL_BypsVlv_ErrMsgs, queue-length=1}, provided-interface=PokeTAIR_y_HTL_BypsVlv_ErrMsgs
      PokeTAIR_y_LTR_BypsVlv_ErrMsgs: server-com-spec{operation=PokeTAIR_y_LTR_BypsVlv_ErrMsgs, queue-length=1}, provided-interface=PokeTAIR_y_LTR_BypsVlv_ErrMsgs
      PokeTAIR_y_RearCabinFanSts: server-com-spec{operation=PokeTAIR_y_RearCabinFanSts, queue-length=1}, provided-interface=PokeTAIR_y_RearCabinFanSts
    behavior IB_TAIR: data-type-mapping=msADTtoIDTMapping, handle-termination-and-restart=NO-SUPPORT
      timing event Event_MedTED: start-on-event=TAIR_MedTED, period=0.02
      timing event Event_MedTEH: start-on-event=TAIR_MedTEH, period=0.1
      165 x operation invoked event:
        Event_FsftTAIR_I_ACCElecCurr: start-on-event=FsftTAIR_I_ACCElecCurr, operation=FsftTAIR_I_ACCElecCurr.FsftTAIR_I_ACCElecCurr
        Event_FsftTAIR_P_ACCompElec_Pwr: start-on-event=FsftTAIR_P_ACCompElec_Pwr, operation=FsftTAIR_P_ACCompElec_Pwr.FsftTAIR_P_ACCompElec_Pwr
        Event_FsftTAIR_Pct_CPV2_ActlPstn: start-on-event=FsftTAIR_Pct_CPV2_ActlPstn, operation=FsftTAIR_Pct_CPV2_ActlPstn.FsftTAIR_Pct_CPV2_ActlPstn
        Event_FsftTAIR_Pct_DrvTmpDr_Pos: start-on-event=FsftTAIR_Pct_DrvTmpDr_Pos, operation=FsftTAIR_Pct_DrvTmpDr_Pos.FsftTAIR_Pct_DrvTmpDr_Pos
        Event_FsftTAIR_Pct_ECM_AirflowRequest: start-on-event=FsftTAIR_Pct_ECM_AirflowRequest, operation=FsftTAIR_Pct_ECM_AirflowRequest.FsftTAIR_Pct_ECM_AirflowRequest
        Event_FsftTAIR_Pct_ECM_RadFanReq: start-on-event=FsftTAIR_Pct_ECM_RadFanReq, operation=FsftTAIR_Pct_ECM_RadFanReq.FsftTAIR_Pct_ECM_RadFanReq
        Event_FsftTAIR_Pct_EEXV_PosAct: start-on-event=FsftTAIR_Pct_EEXV_PosAct, operation=FsftTAIR_Pct_EEXV_PosAct.FsftTAIR_Pct_EEXV_PosAct
        Event_FsftTAIR_Pct_EXV_PosAct: start-on-event=FsftTAIR_Pct_EXV_PosAct, operation=FsftTAIR_Pct_EXV_PosAct.FsftTAIR_Pct_EXV_PosAct
        Event_FsftTAIR_Pct_FrWyVlv_ActlPstn: start-on-event=FsftTAIR_Pct_FrWyVlv_ActlPstn, operation=FsftTAIR_Pct_FrWyVlv_ActlPstn.FsftTAIR_Pct_FrWyVlv_ActlPstn
        Event_FsftTAIR_Pct_FrtBlwrCmd: start-on-event=FsftTAIR_Pct_FrtBlwrCmd, operation=FsftTAIR_Pct_FrtBlwrCmd.FsftTAIR_Pct_FrtBlwrCmd
        Event_FsftTAIR_Pct_HTL_BypsVlv_ActlPstn: start-on-event=FsftTAIR_Pct_HTL_BypsVlv_ActlPstn, operation=FsftTAIR_Pct_HTL_BypsVlv_ActlPstn.FsftTAIR_Pct_HTL_BypsVlv_ActlPstn
        Event_FsftTAIR_Pct_LTR_BypsVlv_ActlPstn: start-on-event=FsftTAIR_Pct_LTR_BypsVlv_ActlPstn, operation=FsftTAIR_Pct_LTR_BypsVlv_ActlPstn.FsftTAIR_Pct_LTR_BypsVlv_ActlPstn
        Event_FsftTAIR_Pct_OEXV_PosAct: start-on-event=FsftTAIR_Pct_OEXV_PosAct, operation=FsftTAIR_Pct_OEXV_PosAct.FsftTAIR_Pct_OEXV_PosAct
        Event_FsftTAIR_Pct_PasTmpDr_Pos: start-on-event=FsftTAIR_Pct_PasTmpDr_Pos, operation=FsftTAIR_Pct_PasTmpDr_Pos.FsftTAIR_Pct_PasTmpDr_Pos
        Event_FsftTAIR_Pct_RrBlwrCmd: start-on-event=FsftTAIR_Pct_RrBlwrCmd, operation=FsftTAIR_Pct_RrBlwrCmd.FsftTAIR_Pct_RrBlwrCmd
        Event_FsftTAIR_Pct_RrTmpDr_Cmd: start-on-event=FsftTAIR_Pct_RrTmpDr_Cmd, operation=FsftTAIR_Pct_RrTmpDr_Cmd.FsftTAIR_Pct_RrTmpDr_Cmd
        Event_FsftTAIR_T_CompBoardTemp: start-on-event=FsftTAIR_T_CompBoardTemp, operation=FsftTAIR_T_CompBoardTemp.FsftTAIR_T_CompBoardTemp
        Event_FsftTAIR_T_CompIGBTTemp: start-on-event=FsftTAIR_T_CompIGBTTemp, operation=FsftTAIR_T_CompIGBTTemp.FsftTAIR_T_CompIGBTTemp
        Event_FsftTAIR_T_EEXV_RefTemp: start-on-event=FsftTAIR_T_EEXV_RefTemp, operation=FsftTAIR_T_EEXV_RefTemp.FsftTAIR_T_EEXV_RefTemp
        Event_FsftTAIR_T_EXV_BoardTemp: start-on-event=FsftTAIR_T_EXV_BoardTemp, operation=FsftTAIR_T_EXV_BoardTemp.FsftTAIR_T_EXV_BoardTemp
        Event_FsftTAIR_T_EXV_RefTemp: start-on-event=FsftTAIR_T_EXV_RefTemp, operation=FsftTAIR_T_EXV_RefTemp.FsftTAIR_T_EXV_RefTemp
        Event_FsftTAIR_T_FtEvapTmp: start-on-event=FsftTAIR_T_FtEvapTmp, operation=FsftTAIR_T_FtEvapTmp.FsftTAIR_T_FtEvapTmp
        Event_FsftTAIR_T_FtEvapTmp_P1C: start-on-event=FsftTAIR_T_FtEvapTmp_P1C, operation=FsftTAIR_T_FtEvapTmp_P1C.FsftTAIR_T_FtEvapTmp_P1C
        Event_FsftTAIR_T_FtEvapTmp_Tgt: start-on-event=FsftTAIR_T_FtEvapTmp_Tgt, operation=FsftTAIR_T_FtEvapTmp_Tgt.FsftTAIR_T_FtEvapTmp_Tgt
        Event_FsftTAIR_T_HtrCoreTmp_Tgt: start-on-event=FsftTAIR_T_HtrCoreTmp_Tgt, operation=FsftTAIR_T_HtrCoreTmp_Tgt.FsftTAIR_T_HtrCoreTmp_Tgt
        Event_FsftTAIR_T_OEXV_RefTemp: start-on-event=FsftTAIR_T_OEXV_RefTemp, operation=FsftTAIR_T_OEXV_RefTemp.FsftTAIR_T_OEXV_RefTemp
        Event_FsftTAIR_T_VhIntTmp: start-on-event=FsftTAIR_T_VhIntTmp, operation=FsftTAIR_T_VhIntTmp.FsftTAIR_T_VhIntTmp
        Event_FsftTAIR_U_CompHVInput: start-on-event=FsftTAIR_U_CompHVInput, operation=FsftTAIR_U_CompHVInput.FsftTAIR_U_CompHVInput
        Event_FsftTAIR_U_EXV_SupplyVolt: start-on-event=FsftTAIR_U_EXV_SupplyVolt, operation=FsftTAIR_U_EXV_SupplyVolt.FsftTAIR_U_EXV_SupplyVolt
        Event_FsftTAIR_U_FrWyVlv_MtrVltg: start-on-event=FsftTAIR_U_FrWyVlv_MtrVltg, operation=FsftTAIR_U_FrWyVlv_MtrVltg.FsftTAIR_U_FrWyVlv_MtrVltg
        Event_FsftTAIR_U_HTL_BypsVlv_MtrVltg: start-on-event=FsftTAIR_U_HTL_BypsVlv_MtrVltg, operation=FsftTAIR_U_HTL_BypsVlv_MtrVltg.FsftTAIR_U_HTL_BypsVlv_MtrVltg
        Event_FsftTAIR_U_LTR_BypsVlv_MtrVltg: start-on-event=FsftTAIR_U_LTR_BypsVlv_MtrVltg, operation=FsftTAIR_U_LTR_BypsVlv_MtrVltg.FsftTAIR_U_LTR_BypsVlv_MtrVltg
        Event_FsftTAIR_b_AGS2_CurrPos: start-on-event=FsftTAIR_b_AGS2_CurrPos, operation=FsftTAIR_b_AGS2_CurrPos.FsftTAIR_b_AGS2_CurrPos
        Event_FsftTAIR_b_AGS_CurrPos: start-on-event=FsftTAIR_b_AGS_CurrPos, operation=FsftTAIR_b_AGS_CurrPos.FsftTAIR_b_AGS_CurrPos
        Event_FsftTAIR_b_EBL_Stat: start-on-event=FsftTAIR_b_EBL_Stat, operation=FsftTAIR_b_EBL_Stat.FsftTAIR_b_EBL_Stat
        Event_FsftTAIR_b_HghRfrgtPresFailSts: start-on-event=FsftTAIR_b_HghRfrgtPresFailSts, operation=FsftTAIR_b_HghRfrgtPresFailSts.FsftTAIR_b_HghRfrgtPresFailSts
        Event_FsftTAIR_b_RearCabinFanSts: start-on-event=FsftTAIR_b_RearCabinFanSts, operation=FsftTAIR_b_RearCabinFanSts.FsftTAIR_b_RearCabinFanSts
        Event_FsftTAIR_e_AGS2_ErrFdb: start-on-event=FsftTAIR_e_AGS2_ErrFdb, operation=FsftTAIR_e_AGS2_ErrFdb.FsftTAIR_e_AGS2_ErrFdb
        Event_FsftTAIR_e_AGS_ErrFdb: start-on-event=FsftTAIR_e_AGS_ErrFdb, operation=FsftTAIR_e_AGS_ErrFdb.FsftTAIR_e_AGS_ErrFdb
        Event_FsftTAIR_e_CompFltStat: start-on-event=FsftTAIR_e_CompFltStat, operation=FsftTAIR_e_CompFltStat.FsftTAIR_e_CompFltStat
        Event_FsftTAIR_e_CompStat: start-on-event=FsftTAIR_e_CompStat, operation=FsftTAIR_e_CompStat.FsftTAIR_e_CompStat
        Event_FsftTAIR_e_EXV_CalStat: start-on-event=FsftTAIR_e_EXV_CalStat, operation=FsftTAIR_e_EXV_CalStat.FsftTAIR_e_EXV_CalStat
        Event_FsftTAIR_e_EXV_Err: start-on-event=FsftTAIR_e_EXV_Err, operation=FsftTAIR_e_EXV_Err.FsftTAIR_e_EXV_Err
        Event_FsftTAIR_e_EXV_Sts: start-on-event=FsftTAIR_e_EXV_Sts, operation=FsftTAIR_e_EXV_Sts.FsftTAIR_e_EXV_Sts
        Event_FsftTAIR_e_FrWyVlv_CalSts: start-on-event=FsftTAIR_e_FrWyVlv_CalSts, operation=FsftTAIR_e_FrWyVlv_CalSts.FsftTAIR_e_FrWyVlv_CalSts
        Event_FsftTAIR_e_FrWyVlv_ErrSts: start-on-event=FsftTAIR_e_FrWyVlv_ErrSts, operation=FsftTAIR_e_FrWyVlv_ErrSts.FsftTAIR_e_FrWyVlv_ErrSts
        Event_FsftTAIR_e_HTL_BypsVlv_CalSts: start-on-event=FsftTAIR_e_HTL_BypsVlv_CalSts, operation=FsftTAIR_e_HTL_BypsVlv_CalSts.FsftTAIR_e_HTL_BypsVlv_CalSts
        Event_FsftTAIR_e_HTL_BypsVlv_ErrSts: start-on-event=FsftTAIR_e_HTL_BypsVlv_ErrSts, operation=FsftTAIR_e_HTL_BypsVlv_ErrSts.FsftTAIR_e_HTL_BypsVlv_ErrSts
        Event_FsftTAIR_e_LTR_BypsVlv_CalSts: start-on-event=FsftTAIR_e_LTR_BypsVlv_CalSts, operation=FsftTAIR_e_LTR_BypsVlv_CalSts.FsftTAIR_e_LTR_BypsVlv_CalSts
        Event_FsftTAIR_e_LTR_BypsVlv_ErrSts: start-on-event=FsftTAIR_e_LTR_BypsVlv_ErrSts, operation=FsftTAIR_e_LTR_BypsVlv_ErrSts.FsftTAIR_e_LTR_BypsVlv_ErrSts
        Event_FsftTAIR_kp_EXV_RefPress: start-on-event=FsftTAIR_kp_EXV_RefPress, operation=FsftTAIR_kp_EXV_RefPress.FsftTAIR_kp_EXV_RefPress
        Event_FsftTAIR_n_CompSpdFdb: start-on-event=FsftTAIR_n_CompSpdFdb, operation=FsftTAIR_n_CompSpdFdb.FsftTAIR_n_CompSpdFdb
        Event_FsftTAIR_p_EEXV_RefPress: start-on-event=FsftTAIR_p_EEXV_RefPress, operation=FsftTAIR_p_EEXV_RefPress.FsftTAIR_p_EEXV_RefPress
        Event_FsftTAIR_p_OEXV_RefPress: start-on-event=FsftTAIR_p_OEXV_RefPress, operation=FsftTAIR_p_OEXV_RefPress.FsftTAIR_p_OEXV_RefPress
        Event_FsftTAIR_y_CPV2_ErrMsgs: start-on-event=FsftTAIR_y_CPV2_ErrMsgs, operation=FsftTAIR_y_CPV2_ErrMsgs.FsftTAIR_y_CPV2_ErrMsgs
        Event_FsftTAIR_y_FrWyVlv_ErrMsgs: start-on-event=FsftTAIR_y_FrWyVlv_ErrMsgs, operation=FsftTAIR_y_FrWyVlv_ErrMsgs.FsftTAIR_y_FrWyVlv_ErrMsgs
        Event_FsftTAIR_y_HTL_BypsVlv_ErrMsgs: start-on-event=FsftTAIR_y_HTL_BypsVlv_ErrMsgs, operation=FsftTAIR_y_HTL_BypsVlv_ErrMsgs.FsftTAIR_y_HTL_BypsVlv_ErrMsgs
        Event_FsftTAIR_y_LTR_BypsVlv_ErrMsgs: start-on-event=FsftTAIR_y_LTR_BypsVlv_ErrMsgs, operation=FsftTAIR_y_LTR_BypsVlv_ErrMsgs.FsftTAIR_y_LTR_BypsVlv_ErrMsgs
        Event_PokeTAIF_DVC_HTempCbnVlv: start-on-event=PokeTAIF_DVC_HTempCbnVlv, operation=PokeTAIF_DVC_HTempCbnVlv.PokeTAIF_DVC_HTempCbnVlv
        Event_PokeTAIF_DVC_LT_Shtoff_VlvCmd: start-on-event=PokeTAIF_DVC_LT_Shtoff_VlvCmd, operation=PokeTAIF_DVC_LT_Shtoff_VlvCmd.PokeTAIF_DVC_LT_Shtoff_VlvCmd
        Event_PokeTAIF_e_DVC_HTCV_Calibration_Start: start-on-event=PokeTAIF_e_DVC_HTCV_Calibration_Start, operation=PokeTAIF_e_DVC_HTCV_Calibration_Start.PokeTAIF_e_DVC_HTCV_Calibration_Start
        Event_PokeTAIR_I_ACCElecCurr: start-on-event=PokeTAIR_I_ACCElecCurr, operation=PokeTAIR_I_ACCElecCurr.PokeTAIR_I_ACCElecCurr
        Event_PokeTAIR_P_ACCompElec_Pwr: start-on-event=PokeTAIR_P_ACCompElec_Pwr, operation=PokeTAIR_P_ACCompElec_Pwr.PokeTAIR_P_ACCompElec_Pwr
        Event_PokeTAIR_Pct_CPV2_ActlPstn: start-on-event=PokeTAIR_Pct_CPV2_ActlPstn, operation=PokeTAIR_Pct_CPV2_ActlPstn.PokeTAIR_Pct_CPV2_ActlPstn
        Event_PokeTAIR_Pct_DrvTmpDr_Pos: start-on-event=PokeTAIR_Pct_DrvTmpDr_Pos, operation=PokeTAIR_Pct_DrvTmpDr_Pos.PokeTAIR_Pct_DrvTmpDr_Pos
        Event_PokeTAIR_Pct_ECM_AirflowRequest: start-on-event=PokeTAIR_Pct_ECM_AirflowRequest, operation=PokeTAIR_Pct_ECM_AirflowRequest.PokeTAIR_Pct_ECM_AirflowRequest
        Event_PokeTAIR_Pct_ECM_RadFanReq: start-on-event=PokeTAIR_Pct_ECM_RadFanReq, operation=PokeTAIR_Pct_ECM_RadFanReq.PokeTAIR_Pct_ECM_RadFanReq
        Event_PokeTAIR_Pct_EEXV_PosAct: start-on-event=PokeTAIR_Pct_EEXV_PosAct, operation=PokeTAIR_Pct_EEXV_PosAct.PokeTAIR_Pct_EEXV_PosAct
        Event_PokeTAIR_Pct_EXV_PosAct: start-on-event=PokeTAIR_Pct_EXV_PosAct, operation=PokeTAIR_Pct_EXV_PosAct.PokeTAIR_Pct_EXV_PosAct
        Event_PokeTAIR_Pct_FrWyVlv_ActlPstn: start-on-event=PokeTAIR_Pct_FrWyVlv_ActlPstn, operation=PokeTAIR_Pct_FrWyVlv_ActlPstn.PokeTAIR_Pct_FrWyVlv_ActlPstn
        Event_PokeTAIR_Pct_FrtBlwrCmd: start-on-event=PokeTAIR_Pct_FrtBlwrCmd, operation=PokeTAIR_Pct_FrtBlwrCmd.PokeTAIR_Pct_FrtBlwrCmd
        Event_PokeTAIR_Pct_HTL_BypsVlv_ActlPstn: start-on-event=PokeTAIR_Pct_HTL_BypsVlv_ActlPstn, operation=PokeTAIR_Pct_HTL_BypsVlv_ActlPstn.PokeTAIR_Pct_HTL_BypsVlv_ActlPstn
        Event_PokeTAIR_Pct_LTR_BypsVlv_ActlPstn: start-on-event=PokeTAIR_Pct_LTR_BypsVlv_ActlPstn, operation=PokeTAIR_Pct_LTR_BypsVlv_ActlPstn.PokeTAIR_Pct_LTR_BypsVlv_ActlPstn
        Event_PokeTAIR_Pct_OEXV_PosAct: start-on-event=PokeTAIR_Pct_OEXV_PosAct, operation=PokeTAIR_Pct_OEXV_PosAct.PokeTAIR_Pct_OEXV_PosAct
        Event_PokeTAIR_Pct_PasTmpDr_Pos: start-on-event=PokeTAIR_Pct_PasTmpDr_Pos, operation=PokeTAIR_Pct_PasTmpDr_Pos.PokeTAIR_Pct_PasTmpDr_Pos
        Event_PokeTAIR_Pct_RrBlwrCmd: start-on-event=PokeTAIR_Pct_RrBlwrCmd, operation=PokeTAIR_Pct_RrBlwrCmd.PokeTAIR_Pct_RrBlwrCmd
        Event_PokeTAIR_Pct_RrTmpDr_Cmd: start-on-event=PokeTAIR_Pct_RrTmpDr_Cmd, operation=PokeTAIR_Pct_RrTmpDr_Cmd.PokeTAIR_Pct_RrTmpDr_Cmd
        Event_PokeTAIR_T_CompBoardTemp: start-on-event=PokeTAIR_T_CompBoardTemp, operation=PokeTAIR_T_CompBoardTemp.PokeTAIR_T_CompBoardTemp
        Event_PokeTAIR_T_CompIGBTTemp: start-on-event=PokeTAIR_T_CompIGBTTemp, operation=PokeTAIR_T_CompIGBTTemp.PokeTAIR_T_CompIGBTTemp
        Event_PokeTAIR_T_EEXV_BoardTemp: start-on-event=PokeTAIR_T_EEXV_BoardTemp, operation=PokeTAIR_T_EEXV_BoardTemp.PokeTAIR_T_EEXV_BoardTemp
        Event_PokeTAIR_T_EEXV_RefTemp: start-on-event=PokeTAIR_T_EEXV_RefTemp, operation=PokeTAIR_T_EEXV_RefTemp.PokeTAIR_T_EEXV_RefTemp
        Event_PokeTAIR_T_EXV_BoardTemp: start-on-event=PokeTAIR_T_EXV_BoardTemp, operation=PokeTAIR_T_EXV_BoardTemp.PokeTAIR_T_EXV_BoardTemp
        Event_PokeTAIR_T_EXV_RefTemp: start-on-event=PokeTAIR_T_EXV_RefTemp, operation=PokeTAIR_T_EXV_RefTemp.PokeTAIR_T_EXV_RefTemp
        Event_PokeTAIR_T_FtEvapTmp: start-on-event=PokeTAIR_T_FtEvapTmp, operation=PokeTAIR_T_FtEvapTmp.PokeTAIR_T_FtEvapTmp
        Event_PokeTAIR_T_FtEvapTmp_P1C: start-on-event=PokeTAIR_T_FtEvapTmp_P1C, operation=PokeTAIR_T_FtEvapTmp_P1C.PokeTAIR_T_FtEvapTmp_P1C
        Event_PokeTAIR_T_FtEvapTmp_Tgt: start-on-event=PokeTAIR_T_FtEvapTmp_Tgt, operation=PokeTAIR_T_FtEvapTmp_Tgt.PokeTAIR_T_FtEvapTmp_Tgt
        Event_PokeTAIR_T_HtrCoreTmp_Tgt: start-on-event=PokeTAIR_T_HtrCoreTmp_Tgt, operation=PokeTAIR_T_HtrCoreTmp_Tgt.PokeTAIR_T_HtrCoreTmp_Tgt
        Event_PokeTAIR_T_OEXV_BoardTemp: start-on-event=PokeTAIR_T_OEXV_BoardTemp, operation=PokeTAIR_T_OEXV_BoardTemp.PokeTAIR_T_OEXV_BoardTemp
        Event_PokeTAIR_T_OEXV_RefTemp: start-on-event=PokeTAIR_T_OEXV_RefTemp, operation=PokeTAIR_T_OEXV_RefTemp.PokeTAIR_T_OEXV_RefTemp
        Event_PokeTAIR_T_VhIntTmp: start-on-event=PokeTAIR_T_VhIntTmp, operation=PokeTAIR_T_VhIntTmp.PokeTAIR_T_VhIntTmp
        Event_PokeTAIR_U_CPV2_MtrVltg: start-on-event=PokeTAIR_U_CPV2_MtrVltg, operation=PokeTAIR_U_CPV2_MtrVltg.PokeTAIR_U_CPV2_MtrVltg
        Event_PokeTAIR_U_CompHVInput: start-on-event=PokeTAIR_U_CompHVInput, operation=PokeTAIR_U_CompHVInput.PokeTAIR_U_CompHVInput
        Event_PokeTAIR_U_EEXV_SupplyVolt: start-on-event=PokeTAIR_U_EEXV_SupplyVolt, operation=PokeTAIR_U_EEXV_SupplyVolt.PokeTAIR_U_EEXV_SupplyVolt
        Event_PokeTAIR_U_EXV_SupplyVolt: start-on-event=PokeTAIR_U_EXV_SupplyVolt, operation=PokeTAIR_U_EXV_SupplyVolt.PokeTAIR_U_EXV_SupplyVolt
        Event_PokeTAIR_U_FrWyVlv_MtrVltg: start-on-event=PokeTAIR_U_FrWyVlv_MtrVltg, operation=PokeTAIR_U_FrWyVlv_MtrVltg.PokeTAIR_U_FrWyVlv_MtrVltg
        Event_PokeTAIR_U_HTL_BypsVlv_MtrVltg: start-on-event=PokeTAIR_U_HTL_BypsVlv_MtrVltg, operation=PokeTAIR_U_HTL_BypsVlv_MtrVltg.PokeTAIR_U_HTL_BypsVlv_MtrVltg
        Event_PokeTAIR_U_HT_CabVlvSts: start-on-event=PokeTAIR_U_HT_CabVlvSts, operation=PokeTAIR_U_HT_CabVlvSts.PokeTAIR_U_HT_CabVlvSts
        Event_PokeTAIR_U_LTR_BypsVlv_MtrVltg: start-on-event=PokeTAIR_U_LTR_BypsVlv_MtrVltg, operation=PokeTAIR_U_LTR_BypsVlv_MtrVltg.PokeTAIR_U_LTR_BypsVlv_MtrVltg
        Event_PokeTAIR_U_OEXV_SupplyVolt: start-on-event=PokeTAIR_U_OEXV_SupplyVolt, operation=PokeTAIR_U_OEXV_SupplyVolt.PokeTAIR_U_OEXV_SupplyVolt
        Event_PokeTAIR_b_ACCompReq: start-on-event=PokeTAIR_b_ACCompReq, operation=PokeTAIR_b_ACCompReq.PokeTAIR_b_ACCompReq
        Event_PokeTAIR_b_AGS2_BoostSts: start-on-event=PokeTAIR_b_AGS2_BoostSts, operation=PokeTAIR_b_AGS2_BoostSts.PokeTAIR_b_AGS2_BoostSts
        Event_PokeTAIR_b_AGS2_CalibrationActv: start-on-event=PokeTAIR_b_AGS2_CalibrationActv, operation=PokeTAIR_b_AGS2_CalibrationActv.PokeTAIR_b_AGS2_CalibrationActv
        Event_PokeTAIR_b_AGS2_ErrMechBreak: start-on-event=PokeTAIR_b_AGS2_ErrMechBreak, operation=PokeTAIR_b_AGS2_ErrMechBreak.PokeTAIR_b_AGS2_ErrMechBreak
        Event_PokeTAIR_b_AGS2_ErrMechStuck: start-on-event=PokeTAIR_b_AGS2_ErrMechStuck, operation=PokeTAIR_b_AGS2_ErrMechStuck.PokeTAIR_b_AGS2_ErrMechStuck
        Event_PokeTAIR_b_AGS2_ErrOverTemp: start-on-event=PokeTAIR_b_AGS2_ErrOverTemp, operation=PokeTAIR_b_AGS2_ErrOverTemp.PokeTAIR_b_AGS2_ErrOverTemp
        Event_PokeTAIR_b_AGS2_ErrOverVolt: start-on-event=PokeTAIR_b_AGS2_ErrOverVolt, operation=PokeTAIR_b_AGS2_ErrOverVolt.PokeTAIR_b_AGS2_ErrOverVolt
        Event_PokeTAIR_b_AGS2_ErrUnderVolt: start-on-event=PokeTAIR_b_AGS2_ErrUnderVolt, operation=PokeTAIR_b_AGS2_ErrUnderVolt.PokeTAIR_b_AGS2_ErrUnderVolt
        Event_PokeTAIR_b_AGS2_ResErr: start-on-event=PokeTAIR_b_AGS2_ResErr, operation=PokeTAIR_b_AGS2_ResErr.PokeTAIR_b_AGS2_ResErr
        Event_PokeTAIR_b_AGS_BoostSts: start-on-event=PokeTAIR_b_AGS_BoostSts, operation=PokeTAIR_b_AGS_BoostSts.PokeTAIR_b_AGS_BoostSts
        Event_PokeTAIR_b_AGS_CalibrationActv: start-on-event=PokeTAIR_b_AGS_CalibrationActv, operation=PokeTAIR_b_AGS_CalibrationActv.PokeTAIR_b_AGS_CalibrationActv
        Event_PokeTAIR_b_AGS_ErrMechBreak: start-on-event=PokeTAIR_b_AGS_ErrMechBreak, operation=PokeTAIR_b_AGS_ErrMechBreak.PokeTAIR_b_AGS_ErrMechBreak
        Event_PokeTAIR_b_AGS_ErrMechStuck: start-on-event=PokeTAIR_b_AGS_ErrMechStuck, operation=PokeTAIR_b_AGS_ErrMechStuck.PokeTAIR_b_AGS_ErrMechStuck
        Event_PokeTAIR_b_AGS_ErrOverTemp: start-on-event=PokeTAIR_b_AGS_ErrOverTemp, operation=PokeTAIR_b_AGS_ErrOverTemp.PokeTAIR_b_AGS_ErrOverTemp
        Event_PokeTAIR_b_AGS_ErrOverVolt: start-on-event=PokeTAIR_b_AGS_ErrOverVolt, operation=PokeTAIR_b_AGS_ErrOverVolt.PokeTAIR_b_AGS_ErrOverVolt
        Event_PokeTAIR_b_AGS_ErrUnderVolt: start-on-event=PokeTAIR_b_AGS_ErrUnderVolt, operation=PokeTAIR_b_AGS_ErrUnderVolt.PokeTAIR_b_AGS_ErrUnderVolt
        Event_PokeTAIR_b_AGS_ResErr: start-on-event=PokeTAIR_b_AGS_ResErr, operation=PokeTAIR_b_AGS_ResErr.PokeTAIR_b_AGS_ResErr
        Event_PokeTAIR_b_CPV2_RsErr: start-on-event=PokeTAIR_b_CPV2_RsErr, operation=PokeTAIR_b_CPV2_RsErr.PokeTAIR_b_CPV2_RsErr
        Event_PokeTAIR_b_CompSpdIncrReq: start-on-event=PokeTAIR_b_CompSpdIncrReq, operation=PokeTAIR_b_CompSpdIncrReq.PokeTAIR_b_CompSpdIncrReq
        Event_PokeTAIR_b_EEXV_CalRq: start-on-event=PokeTAIR_b_EEXV_CalRq, operation=PokeTAIR_b_EEXV_CalRq.PokeTAIR_b_EEXV_CalRq
        Event_PokeTAIR_b_EEXV_RspErr: start-on-event=PokeTAIR_b_EEXV_RspErr, operation=PokeTAIR_b_EEXV_RspErr.PokeTAIR_b_EEXV_RspErr
        Event_PokeTAIR_b_EXV_CalRq: start-on-event=PokeTAIR_b_EXV_CalRq, operation=PokeTAIR_b_EXV_CalRq.PokeTAIR_b_EXV_CalRq
        Event_PokeTAIR_b_EXV_RspErr: start-on-event=PokeTAIR_b_EXV_RspErr, operation=PokeTAIR_b_EXV_RspErr.PokeTAIR_b_EXV_RspErr
        Event_PokeTAIR_b_FrWyVlv_RsErr: start-on-event=PokeTAIR_b_FrWyVlv_RsErr, operation=PokeTAIR_b_FrWyVlv_RsErr.PokeTAIR_b_FrWyVlv_RsErr
        Event_PokeTAIR_b_HTL_BypsVlv_RsErr: start-on-event=PokeTAIR_b_HTL_BypsVlv_RsErr, operation=PokeTAIR_b_HTL_BypsVlv_RsErr.PokeTAIR_b_HTL_BypsVlv_RsErr
        Event_PokeTAIR_b_HghRfrgtPresFailSts: start-on-event=PokeTAIR_b_HghRfrgtPresFailSts, operation=PokeTAIR_b_HghRfrgtPresFailSts.PokeTAIR_b_HghRfrgtPresFailSts
        Event_PokeTAIR_b_LTR_BypsVlv_RsErr: start-on-event=PokeTAIR_b_LTR_BypsVlv_RsErr, operation=PokeTAIR_b_LTR_BypsVlv_RsErr.PokeTAIR_b_LTR_BypsVlv_RsErr
        Event_PokeTAIR_b_OEXV_CalRq: start-on-event=PokeTAIR_b_OEXV_CalRq, operation=PokeTAIR_b_OEXV_CalRq.PokeTAIR_b_OEXV_CalRq
        Event_PokeTAIR_b_OEXV_RspErr: start-on-event=PokeTAIR_b_OEXV_RspErr, operation=PokeTAIR_b_OEXV_RspErr.PokeTAIR_b_OEXV_RspErr
        Event_PokeTAIR_b_RespErr_EAC: start-on-event=PokeTAIR_b_RespErr_EAC, operation=PokeTAIR_b_RespErr_EAC.PokeTAIR_b_RespErr_EAC
        Event_PokeTAIR_b_WinshldDfrst: start-on-event=PokeTAIR_b_WinshldDfrst, operation=PokeTAIR_b_WinshldDfrst.PokeTAIR_b_WinshldDfrst
        Event_PokeTAIR_e_AGS2_CalibrationSts: start-on-event=PokeTAIR_e_AGS2_CalibrationSts, operation=PokeTAIR_e_AGS2_CalibrationSts.PokeTAIR_e_AGS2_CalibrationSts
        Event_PokeTAIR_e_AGS2_CurrPos_LIN: start-on-event=PokeTAIR_e_AGS2_CurrPos_LIN, operation=PokeTAIR_e_AGS2_CurrPos_LIN.PokeTAIR_e_AGS2_CurrPos_LIN
        Event_PokeTAIR_e_AGS2_ErrFdb: start-on-event=PokeTAIR_e_AGS2_ErrFdb, operation=PokeTAIR_e_AGS2_ErrFdb.PokeTAIR_e_AGS2_ErrFdb
        Event_PokeTAIR_e_AGS_CalibrationSts: start-on-event=PokeTAIR_e_AGS_CalibrationSts, operation=PokeTAIR_e_AGS_CalibrationSts.PokeTAIR_e_AGS_CalibrationSts
        Event_PokeTAIR_e_AGS_CurrPos_LIN: start-on-event=PokeTAIR_e_AGS_CurrPos_LIN, operation=PokeTAIR_e_AGS_CurrPos_LIN.PokeTAIR_e_AGS_CurrPos_LIN
        Event_PokeTAIR_e_AGS_ErrFdb: start-on-event=PokeTAIR_e_AGS_ErrFdb, operation=PokeTAIR_e_AGS_ErrFdb.PokeTAIR_e_AGS_ErrFdb
        Event_PokeTAIR_e_CPV2_CalSts: start-on-event=PokeTAIR_e_CPV2_CalSts, operation=PokeTAIR_e_CPV2_CalSts.PokeTAIR_e_CPV2_CalSts
        Event_PokeTAIR_e_CPV2_ErrSts: start-on-event=PokeTAIR_e_CPV2_ErrSts, operation=PokeTAIR_e_CPV2_ErrSts.PokeTAIR_e_CPV2_ErrSts
        Event_PokeTAIR_e_CompFltStat: start-on-event=PokeTAIR_e_CompFltStat, operation=PokeTAIR_e_CompFltStat.PokeTAIR_e_CompFltStat
        Event_PokeTAIR_e_CompStat: start-on-event=PokeTAIR_e_CompStat, operation=PokeTAIR_e_CompStat.PokeTAIR_e_CompStat
        Event_PokeTAIR_e_EEXV_CalStat: start-on-event=PokeTAIR_e_EEXV_CalStat, operation=PokeTAIR_e_EEXV_CalStat.PokeTAIR_e_EEXV_CalStat
        Event_PokeTAIR_e_EEXV_Err: start-on-event=PokeTAIR_e_EEXV_Err, operation=PokeTAIR_e_EEXV_Err.PokeTAIR_e_EEXV_Err
        Event_PokeTAIR_e_EEXV_Sts: start-on-event=PokeTAIR_e_EEXV_Sts, operation=PokeTAIR_e_EEXV_Sts.PokeTAIR_e_EEXV_Sts
        Event_PokeTAIR_e_EXV_CalStat: start-on-event=PokeTAIR_e_EXV_CalStat, operation=PokeTAIR_e_EXV_CalStat.PokeTAIR_e_EXV_CalStat
        Event_PokeTAIR_e_EXV_Err: start-on-event=PokeTAIR_e_EXV_Err, operation=PokeTAIR_e_EXV_Err.PokeTAIR_e_EXV_Err
        Event_PokeTAIR_e_EXV_Sts: start-on-event=PokeTAIR_e_EXV_Sts, operation=PokeTAIR_e_EXV_Sts.PokeTAIR_e_EXV_Sts
        Event_PokeTAIR_e_FrWyVlv_CalSts: start-on-event=PokeTAIR_e_FrWyVlv_CalSts, operation=PokeTAIR_e_FrWyVlv_CalSts.PokeTAIR_e_FrWyVlv_CalSts
        Event_PokeTAIR_e_FrWyVlv_ErrSts: start-on-event=PokeTAIR_e_FrWyVlv_ErrSts, operation=PokeTAIR_e_FrWyVlv_ErrSts.PokeTAIR_e_FrWyVlv_ErrSts
        Event_PokeTAIR_e_HTL_BypsVlv_CalSts: start-on-event=PokeTAIR_e_HTL_BypsVlv_CalSts, operation=PokeTAIR_e_HTL_BypsVlv_CalSts.PokeTAIR_e_HTL_BypsVlv_CalSts
        Event_PokeTAIR_e_HTL_BypsVlv_ErrSts: start-on-event=PokeTAIR_e_HTL_BypsVlv_ErrSts, operation=PokeTAIR_e_HTL_BypsVlv_ErrSts.PokeTAIR_e_HTL_BypsVlv_ErrSts
        Event_PokeTAIR_e_LTR_BypsVlv_CalSts: start-on-event=PokeTAIR_e_LTR_BypsVlv_CalSts, operation=PokeTAIR_e_LTR_BypsVlv_CalSts.PokeTAIR_e_LTR_BypsVlv_CalSts
        Event_PokeTAIR_e_LTR_BypsVlv_ErrSts: start-on-event=PokeTAIR_e_LTR_BypsVlv_ErrSts, operation=PokeTAIR_e_LTR_BypsVlv_ErrSts.PokeTAIR_e_LTR_BypsVlv_ErrSts
        Event_PokeTAIR_e_OEXV_CalStat: start-on-event=PokeTAIR_e_OEXV_CalStat, operation=PokeTAIR_e_OEXV_CalStat.PokeTAIR_e_OEXV_CalStat
        Event_PokeTAIR_e_OEXV_Err: start-on-event=PokeTAIR_e_OEXV_Err, operation=PokeTAIR_e_OEXV_Err.PokeTAIR_e_OEXV_Err
        Event_PokeTAIR_e_OEXV_Sts: start-on-event=PokeTAIR_e_OEXV_Sts, operation=PokeTAIR_e_OEXV_Sts.PokeTAIR_e_OEXV_Sts
        Event_PokeTAIR_e_RearDefrostSts: start-on-event=PokeTAIR_e_RearDefrostSts, operation=PokeTAIR_e_RearDefrostSts.PokeTAIR_e_RearDefrostSts
        Event_PokeTAIR_kp_EXV_RefPress: start-on-event=PokeTAIR_kp_EXV_RefPress, operation=PokeTAIR_kp_EXV_RefPress.PokeTAIR_kp_EXV_RefPress
        Event_PokeTAIR_n_CompSpdFdb: start-on-event=PokeTAIR_n_CompSpdFdb, operation=PokeTAIR_n_CompSpdFdb.PokeTAIR_n_CompSpdFdb
        Event_PokeTAIR_p_EEXV_RefPress: start-on-event=PokeTAIR_p_EEXV_RefPress, operation=PokeTAIR_p_EEXV_RefPress.PokeTAIR_p_EEXV_RefPress
        Event_PokeTAIR_p_OEXV_RefPress: start-on-event=PokeTAIR_p_OEXV_RefPress, operation=PokeTAIR_p_OEXV_RefPress.PokeTAIR_p_OEXV_RefPress
        Event_PokeTAIR_y_CPV2_ErrMsgs: start-on-event=PokeTAIR_y_CPV2_ErrMsgs, operation=PokeTAIR_y_CPV2_ErrMsgs.PokeTAIR_y_CPV2_ErrMsgs
        Event_PokeTAIR_y_FrWyVlv_ErrMsgs: start-on-event=PokeTAIR_y_FrWyVlv_ErrMsgs, operation=PokeTAIR_y_FrWyVlv_ErrMsgs.PokeTAIR_y_FrWyVlv_ErrMsgs
        Event_PokeTAIR_y_HTL_BypsVlv_ErrMsgs: start-on-event=PokeTAIR_y_HTL_BypsVlv_ErrMsgs, operation=PokeTAIR_y_HTL_BypsVlv_ErrMsgs.PokeTAIR_y_HTL_BypsVlv_ErrMsgs
        Event_PokeTAIR_y_LTR_BypsVlv_ErrMsgs: start-on-event=PokeTAIR_y_LTR_BypsVlv_ErrMsgs, operation=PokeTAIR_y_LTR_BypsVlv_ErrMsgs.PokeTAIR_y_LTR_BypsVlv_ErrMsgs
        Event_PokeTAIR_y_RearCabinFanSts: start-on-event=PokeTAIR_y_RearCabinFanSts, operation=PokeTAIR_y_RearCabinFanSts.PokeTAIR_y_RearCabinFanSts
      init event Event_TAIR_ac_Init: start-on-event=TAIR_ac_Init
      init event Event_PwrOn: start-on-event=TAIR_PwrOn
      19 x data received event:
        Event_Routine_RC130D_EXVValCal: start-on-event=Routine_RC130D_EXVValCal, data=VeDCAB_e_Routine_RC130D_EXVValCal_Op.Value
        Event_Routine_RC1333_ACRefExpValActDCal: start-on-event=Routine_RC1333_ACRefExpValActDCal, data=VeDCAB_e_Routine_RC1333_ACRefExpValActDCal_Op.Value
        Event_Routine_RC1332_ACRefExpValActCCal: start-on-event=Routine_RC1332_ACRefExpValActCCal, data=VeDCAB_e_Routine_RC1332_ACRefExpValActCCal_Op.Value
        Event_IOControl_IOCD001_HigTemShuVal: start-on-event=IOControl_IOCD001_HigTemShuVal, data=VeDCAB_e_IOControl_IOCD001_HigTemShuVal_Op.Value
        Event_IOControl_IOCD004_RadFanDutCycle: start-on-event=IOControl_IOCD004_RadFanDutCycle, data=VeDCAB_e_IOControl_IOCD004_RadFanDutCycle_Op.Value
        Event_IOControl_IOCDOIC_PropSysCoolCntrlValvA: start-on-event=IOControl_IOCDOIC_PropSysCoolCntrlValvA, data=VeDCAB_e_IOControl_IOCDOIC_PropSysCoolCntrlValvA_Op.Value
        Event_IOControl_IOCD022_PropSysCoolCntrlValvB: start-on-event=IOControl_IOCD022_PropSysCoolCntrlValvB, data=VeDCAB_e_IOControl_IOCD022_PropSysCoolCntrlValvB_Op.Value
        Event_IOControl_IOCD023_PropSysCoolCntrlValvC: start-on-event=IOControl_IOCD023_PropSysCoolCntrlValvC, data=VeDCAB_e_IOControl_IOCD023_PropSysCoolCntrlValvC_Op.Value
        Event_IOControl_IOCD031_ACRefrExpValvActACntrl: start-on-event=IOControl_IOCD031_ACRefrExpValvActACntrl, data=VeDCAB_e_IOControl_IOCD031_ACRefrExpValvActACntrl_Op.Value
        Event_IOControl_IOCD032_ACRefrExpValvActCCntrl: start-on-event=IOControl_IOCD032_ACRefrExpValvActCCntrl, data=VeDCAB_e_IOControl_IOCD032_ACRefrExpValvActCCntrl_Op.Value
        Event_IOControl_IOCD033_ACRefrExpValvActDCntrl: start-on-event=IOControl_IOCD033_ACRefrExpValvActDCntrl, data=VeDCAB_e_IOControl_IOCD033_ACRefrExpValvActDCntrl_Op.Value
        Event_Routine_RC1314_ActGriShu2Cal: start-on-event=Routine_RC1314_ActGriShu2Cal, data=VeDCAB_e_Routine_RC1314_ActGriShu2Cal_Op.Value
        Event_Routine_RC1313_ActGriShu1Cal: start-on-event=Routine_RC1313_ActGriShu1Cal, data=VeDCAB_e_Routine_RC1313_ActGriShu1Cal_Op.Value
        Event_IOControl_IOCD013_CompSpdTgt: start-on-event=IOControl_IOCD013_CompSpdTgt, data=VeDCAB_e_IOControl_IOCD013_CompSpdTgt_Op.Value
        Event_IOControl_IOCD025_AGS_PstnCmnd: start-on-event=IOControl_IOCD025_AGS_PstnCmnd, data=VeDCAB_e_IOControl_IOCD025_AGS_PstnCmnd_Op.Value
        Event_IOControl_IOCD002_FtRfgtShtoff_VlvCmd: start-on-event=IOControl_IOCD002_FtRfgtShtoff_VlvCmd, data=VeDCAB_e_IOControl_IOCD002_FtRfgtShtoff_VlvCmd_Op.Value
        Event_IOControl_IOCD026_AGS2_PstnCmnd: start-on-event=IOControl_IOCD026_AGS2_PstnCmnd, data=VeDCAB_e_IOControl_IOCD026_AGS2_PstnCmnd_Op.Value
        Event_IOControl_IOCD01F_ACRefrExpValvActACntrl: start-on-event=IOControl_IOCD01F_ACRefrExpValvActACntrl, data=VeDCAB_e_IOControl_IOCD01F_ACRefrExpValvActACntrl_Op.Value
        Event_IOControl_IOCD007_ChlrRfgtShtoff_VlvCmd: start-on-event=IOControl_IOCD007_ChlrRfgtShtoff_VlvCmd, data=VeDCAB_e_IOControl_IOCD007_ChlrRfgtShtoff_VlvCmd_Op.Value
      explicit-inter-runnable-variables:
        200 x data, all with category=VALUE, sw-calibration-access=READ-ONLY:
          VeTAIR_U_HT_CabVlvSts_write_IRV: type=Float, init-value=0
          VeTAIR_b_HT_CabVlvStsFA_write_IRV: type=Boolean, init-value=0
          VeTAIF_e_HT_Shtoff_VlvCmd_IO_CntrlSt_write_IRV: type=TeTAIR_e_IO_CntrlSt, init-value=CeTAIR_e_Return_Control_to_ECU
          VeTAIF_b_HT_Shtoff_VlvCmd_write_IRV: type=Boolean, init-value=0
          VeTAIF_e_FtRfgtShtoff_VlvCmd_IO_CntrlSt_write_IRV: type=TeTAIR_e_IO_CntrlSt, init-value=CeTAIR_e_Return_Control_to_ECU
          VeTAIF_b_FtRfgtShtoff_VlvCmd_write_IRV: type=Boolean, init-value=0
          VeTAIF_e_ChlrRfgtShtoff_VlvCmd_IRV: type=TeTAIR_e_IO_CntrlSt, init-value=CeTAIR_e_Return_Control_to_ECU
          VeTAIF_b_ChlrRfgtShtoff_VlvCmd_IRV: type=Boolean, init-value=0
          VeTAIF_e_HT_CabVlvCmd_IO_CntrlSt_write_IRV: type=TeTAIR_e_IO_CntrlSt, init-value=CeTAIR_e_Return_Control_to_ECU
          VeTAIF_Pct_HT_CabVlvCmd_write_IRV: type=Float, init-value=0
          VeTAIF_e_DVC_HTCV_Calibration_Start_write_IRV: type=TeTAIR_e_DVC_HTCV_Calibration, init-value=CeTAIR_e_DVC_HTCV_Calibration_Start
          VeTAIR_Pct_FrWyVlv_ActlPstn_write_IRV: type=Float, init-value=0
          VeTAIR_b_FrWyVlv_ActlPstnFA_write_IRV: type=Boolean, init-value=0
          VeTAIR_e_FrWyVlv_CalSts_write_IRV: type=TeTAIR_e_CPV_Calibration_Sts, init-value=CeTAIR_e_CPV_Calibration_Complete
          VeTAIR_b_FrWyVlv_RsErr_write_IRV: type=Boolean, init-value=0
          VeTAIR_e_FrWyVlv_ErrSts_write_IRV: type=TeTAIR_e_CPV_Status, init-value=CeTAIR_e_CPV_Status_OK
          VeTAIR_y_FrWyVlv_ErrMsgs_write_IRV: type=UInt16, init-value=0
          VeTAIR_b_FrWyVlv_ErrMsgsFA_write_IRV: type=Boolean, init-value=0
          VeTAIR_U_FrWyVlv_MtrVltg_write_IRV: type=Float, init-value=0
          VeTAIF_e_CPV_VlvCmd_IO_CntrlSt_write_IRV: type=TeTAIR_e_IO_CntrlSt, init-value=CeTAIR_e_Return_Control_to_ECU
          VeTAIF_Pct_CPV_VlvCmd_write_IRV: type=Float, init-value=0
          VeTAIR_Pct_EXV_PosAct_write_IRV: type=Float, init-value=0
          VeTAIR_b_EXV_PosActFA_write_IRV: type=Boolean, init-value=0
          VeTAIR_e_EXV_CalStat_write_IRV: type=TeTAIR_e_EXV_Calibration_Sts, init-value=CeTAIR_e_EXV_Calibration_Complete
          VeTAIR_b_EXV_CalRq_write_IRV: type=Boolean, init-value=0
          VeTAIR_b_EXV_RspErr_write_IRV: type=Boolean, init-value=0
          VeTAIR_e_EXV_Sts_write_IRV: type=TeTAIR_e_EXV_Status, init-value=CeTAIR_e_EXV_Status_OK
          VeTAIR_e_EXV_Err_write_IRV: type=TeTAIR_e_EXV_ErrorMsg, init-value=CeTAIR_e_EXV_ErrorMsg_OK
          VeTAIR_U_EXV_SupplyVolt_write_IRV: type=Float, init-value=0
          VeTAIR_kp_EXV_RefPress_write_IRV: type=Float, init-value=0
          VeTAIR_b_EXV_RefPressFA_write_IRV: type=Boolean, init-value=0
          VeTAIR_T_EXV_BoardTemp_write_IRV: type=Float, init-value=0
          VeTAIR_T_EXV_RefTemp_write_IRV: type=Float, init-value=0
          VeTAIR_b_EXV_RefTempFA_write_IRV: type=Boolean, init-value=0
          VeTAIR_Pct_LTR_BypsVlv_ActlPstn_write_IRV: type=Float, init-value=0
          VeTAIR_b_LTR_BypsVlv_ActlPstnFA_write_IRV: type=Boolean, init-value=0
          VeTAIR_e_LTR_BypsVlv_CalSts_write_IRV: type=TeTAIR_e_CPV_Calibration_Sts, init-value=CeTAIR_e_CPV_Calibration_Complete
          VeTAIR_b_LTR_BypsVlv_CalStsFA_write_IRV: type=Boolean, init-value=0
          VeTAIR_b_LTR_BypsVlv_RsErr_write_IRV: type=Boolean, init-value=0
          VeTAIR_e_LTR_BypsVlv_ErrSts_write_IRV: type=TeTAIR_e_CPV_Status, init-value=CeTAIR_e_CPV_Status_OK
          VeTAIR_b_LTR_BypsVlv_ErrStsFA_write_IRV: type=Boolean, init-value=0
          VeTAIR_y_LTR_BypsVlv_ErrMsgs_write_IRV: type=UInt16, init-value=0
          VeTAIR_b_LTR_BypsVlv_ErrMsgsFA_write_IRV: type=Boolean, init-value=0
          VeTAIR_U_LTR_BypsVlv_MtrVltg_write_IRV: type=Float, init-value=0
          VeTAIR_b_LTR_BypsVlv_MtrVltgFA_write_IRV: type=Boolean, init-value=0
          VeTAIR_Pct_HTL_BypsVlv_ActlPstn_write_IRV: type=Float, init-value=0
          VeTAIR_b_HTL_BypsVlv_ActlPstnFA_write_IRV: type=Boolean, init-value=0
          VeTAIR_e_HTL_BypsVlv_CalSts_write_IRV: type=TeTAIR_e_CPV_Calibration_Sts, init-value=CeTAIR_e_CPV_Calibration_Complete
          VeTAIR_b_HTL_BypsVlv_CalStsFA_write_IRV: type=Boolean, init-value=0
          VeTAIR_b_HTL_BypsVlv_RsErr_write_IRV: type=Boolean, init-value=0
          VeTAIR_e_HTL_BypsVlv_ErrSts_write_IRV: type=TeTAIR_e_CPV_Status, init-value=CeTAIR_e_CPV_Status_OK
          VeTAIR_b_HTL_BypsVlv_ErrStsFA_write_IRV: type=Boolean, init-value=0
          VeTAIR_y_HTL_BypsVlv_ErrMsgs_write_IRV: type=UInt16, init-value=0
          VeTAIR_b_HTL_BypsVlv_ErrMsgsFA_write_IRV: type=Boolean, init-value=0
          VeTAIR_U_HTL_BypsVlv_MtrVltg_write_IRV: type=Float, init-value=0
          VeTAIR_b_HTL_BypsVlv_MtrVltgFA_write_IRV: type=Boolean, init-value=0
          VeTAIF_e_EXV_VlvCmd_IO_CntrlSt_write_IRV: type=TeTAIR_e_IO_CntrlSt, init-value=CeTAIR_e_Return_Control_to_ECU
          VeTAIF_Pct_EXV_VlvCmd_write_IRV: type=Float, init-value=0
          VeTAIF_b_DVC_EXV_Calibration_Start_IRV: type=Boolean, init-value=0
          VeTAIF_e_LT_Shtoff_VlvCmd_IO_CntrlSt_write_IRV: type=TeTAIR_e_IO_CntrlSt, init-value=CeTAIR_e_Return_Control_to_ECU
          VeTAIF_b_LT_Shtoff_VlvCmd_write_IRV: type=Boolean, init-value=0
          VeTAIF_Pct_LTR_BypsVlv_Cmd_write_IRV: type=Float, init-value=0
          VeTAIF_e_LTR_BypsVlv_IO_CntrlSt_write_IRV: type=TeTAIR_e_IO_CntrlSt, init-value=CeTAIR_e_Return_Control_to_ECU
          VeTAIF_Pct_HTL_BypsVlv_Cmd_write_IRV: type=Float, init-value=0
          VeTAIF_e_HTL_BypsVlv_IO_CntrlSt_write_IRV: type=TeTAIR_e_IO_CntrlSt, init-value=CeTAIR_e_Return_Control_to_ECU
          VeTAIR_Pct_EEXV_PosAct_write_IRV: type=Float, init-value=0
          VeTAIR_b_EEXV_PosActFA_write_IRV: type=Boolean, init-value=0
          VeTAIR_e_EEXV_CalStat_write_IRV: type=TeTAIR_e_EXV_Calibration_Sts, init-value=CeTAIR_e_EXV_Calibration_Complete
          VeTAIR_b_EEXV_CalRq_write_IRV: type=Boolean, init-value=0
          VeTAIR_b_EEXV_RspErr_write_IRV: type=Boolean, init-value=0
          VeTAIR_e_EEXV_Sts_write_IRV: type=TeTAIR_e_EXV_Status, init-value=CeTAIR_e_EXV_Status_OK
          VeTAIR_e_EEXV_Err_write_IRV: type=TeTAIR_e_EXV_ErrorMsg, init-value=CeTAIR_e_EXV_ErrorMsg_OK
          VeTAIR_U_EEXV_SupplyVolt_write_IRV: type=Float, init-value=0
          VeTAIR_p_EEXV_RefPress_write_IRV: type=Float, init-value=0
          VeTAIR_b_EEXV_RefPressFA_write_IRV: type=Boolean, init-value=0
          VeTAIR_T_EEXV_BoardTemp_write_IRV: type=Float, init-value=0
          VeTAIR_T_EEXV_RefTemp_write_IRV: type=Float, init-value=0
          VeTAIR_b_EEXV_RefTempFA_write_IRV: type=Boolean, init-value=0
          VeTAIR_Pct_OEXV_PosAct_write_IRV: type=Float, init-value=0
          VeTAIR_b_OEXV_PosActFA_write_IRV: type=Boolean, init-value=0
          VeTAIR_e_OEXV_CalStat_write_IRV: type=TeTAIR_e_EXV_Calibration_Sts, init-value=CeTAIR_e_EXV_Calibration_Complete
          VeTAIR_b_OEXV_CalRq_write_IRV: type=Boolean, init-value=0
          VeTAIR_b_OEXV_RspErr_write_IRV: type=Boolean, init-value=0
          VeTAIR_e_OEXV_Sts_write_IRV: type=TeTAIR_e_EXV_Status, init-value=CeTAIR_e_EXV_Status_OK
          VeTAIR_e_OEXV_Err_write_IRV: type=TeTAIR_e_EXV_ErrorMsg, init-value=CeTAIR_e_EXV_ErrorMsg_OK
          VeTAIR_U_OEXV_SupplyVolt_write_IRV: type=Float, init-value=0
          VeTAIR_T_OEXV_BoardTemp_write_IRV: type=Float, init-value=0
          VeTAIR_p_OEXV_RefPress_write_IRV: type=Float, init-value=0
          VeTAIR_b_OEXV_RefPressFA_write_IRV: type=Boolean, init-value=0
          VeTAIR_T_OEXV_RefTemp_write_IRV: type=Float, init-value=0
          VeTAIR_b_OEXV_RefTempFA_write_IRV: type=Boolean, init-value=0
          VeTAIF_e_EEXV_VlvCmd_IO_CntrlSt_write_IRV: type=TeTAIR_e_IO_CntrlSt, init-value=CeTAIR_e_Return_Control_to_ECU
          VeTAIF_Pct_EEXV_VlvCmd_write_IRV: type=Float, init-value=0
          VeTAIF_b_DVC_EEXV_Calibration_Start_IRV: type=Boolean, init-value=0
          VeTAIF_e_OEXV_VlvCmd_IO_CntrlSt_write_IRV: type=TeTAIR_e_IO_CntrlSt, init-value=CeTAIR_e_Return_Control_to_ECU
          VeTAIF_Pct_OEXV_VlvCmd_write_IRV: type=Float, init-value=0
          VeTAIF_b_DVC_OEXV_Calibration_Start_IRV: type=Boolean, init-value=0
          VeTAIR_Pct_HTRBV_ActuatorPosTrgt_write_IRV: type=Float, init-value=0
          FsftTAIR_Pct_HTRBV_ActuatorPosActFA_write_IRV: type=Boolean, init-value=0
          VeTAIR_T_HTRBV_EcuTemp_write_IRV: type=Float, init-value=0
          VeTAIR_U_HTRBV_EcuVoltage_write_IRV: type=Float, init-value=0
          VeTAIR_b_HTRBV_ResponseError_write_IRV: type=Boolean, init-value=0
          PokeTAIR_Pct_HTRBV_ActuatorPosAct_write_IRV: type=Float, init-value=0
          VeTAIR_b_HTRBV_SelfCalReq_write_IRV: type=Boolean, init-value=0
          VeTAIR_e_HTRBV_Err_Ecu_write_IRV: type=TeTAIR_e_HTRBV_Err_Ecu, init-value=CeTAIR_e_NoEcuError
          VeTAIR_e_HTRBV_Err_Motor_write_IRV: type=TeTAIR_e_HTRBV_Err_Motor, init-value=CeTAIR_e_NoMotorError
          VeTAIR_e_HTRBV_Err_Voltage_write_IRV: type=TeTAIR_e_HTRBV_Err_Voltage, init-value=CeTAIR_e_NoVoltError
          VeTAIR_e_HTRBV_ErrLinCom_write_IRV: type=TeTAIR_e_HTRBV_ErrLinCom, init-value=CeTAIR_e_LINComNoErrors
          VeTAIR_e_HTRBV_ErrPosition_write_IRV: type=TeTAIR_e_HTRBV_ErrPosition, init-value=CeTAIR_e_NoPosError
          VeTAIR_e_HTRBV_SystemState_write_IRV: type=TeTAIR_e_HTRBV_SystemState, init-value=CeTAIR_e_Normal
          VeTAIR_Pct_CPV2_ActlPstn_write_IRV: type=Float, init-value=0
          VeTAIR_b_CPV2_ActlPstnFA_write_IRV: type=Boolean, init-value=0
          VeTAIR_y_CPV2_ErrMsgs_write_IRV: type=UInt16, init-value=0
          VeTAIR_b_CPV2_ErrMsgsFA_write_IRV: type=Boolean, init-value=0
          VeTAIR_U_CPV2_MtrVltg_write_IRV: type=Float, init-value=0
          VeTAIR_e_CPV2_ErrSts_write_IRV: type=TeTAIR_e_CPV_Status, init-value=CeTAIR_e_CPV_Status_OK
          VeTAIR_b_CPV2_RsErr_write_IRV: type=Boolean, init-value=0
          VeTAIR_e_CPV2_CalSts_write_IRV: type=TeTAIR_e_CPV_Calibration_Sts, init-value=CeTAIR_e_CPV_Calibration_Complete
          VeTAIR_Pct_ECM_RadFanReq_write_IRV: type=Float, init-value=0
          VeTAIR_b_ECM_RadFanReqFA_write_IRV: type=Boolean, init-value=0
          VeTAIF_e_RadFanCmd_IO_CntrlSt_write_IRV: type=TeTAIR_e_IO_CntrlSt, init-value=CeTAIR_e_Return_Control_to_ECU
          VeTAIF_Pct_RadFanCmd_write_IRV: type=Float, init-value=0
          VeTAIR_Pct_ECM_AirflowRequest_write_IRV: type=Float, init-value=0
          VeTAIR_b_ECM_AirflowRequestFA_write_IRV: type=Boolean, init-value=0
          VeTAIR_n_CompSpdFdb_write_IRV: type=Float, init-value=0
          VeTAIR_b_CompSpdFdbFA_write_IRV: type=Boolean, init-value=0
          VeTAIR_P_ACCompElec_Pwr_write_IRV: type=Float, init-value=0
          VeTAIR_b_ACCompElec_PwrFA_write_IRV: type=Boolean, init-value=0
          VeTAIR_e_CompStat_write_IRV: type=TeTAIR_e_CompStat, init-value=CeTAIR_e_NormalOp
          VeTAIR_e_CompFltStat_write_IRV: type=TeTAIR_e_CompFltSts, init-value=CeTAIR_e_CompFltSts_NoFault
          VeTAIR_b_CompSpdIncrReq_write_IRV: type=Boolean, init-value=0
          VeTAIR_I_ACCElecCurr_write_IRV: type=Float, init-value=0
          VeTAIR_U_CompHVInput_write_IRV: type=Float, init-value=0
          VeTAIR_b_CompHVInputFA_write_IRV: type=Boolean, init-value=0
          VeTAIR_b_ACCompReq_write_IRV: type=Boolean, init-value=0
          VeTAIR_b_RespErr_EAC_write_IRV: type=Boolean, init-value=0
          VeTAIR_T_CompBoardTemp_write_IRV: type=Float, init-value=0
          VeTAIR_b_CompBoardTempFA_write_IRV: type=Boolean, init-value=0
          VeTAIR_T_CompIGBTTemp_write_IRV: type=Float, init-value=0
          VeTAIR_b_CompIGBTTempFA_write_IRV: type=Boolean, init-value=0
          VeTAIR_T_FtEvapTmp_write_IRV: type=Float, init-value=0
          VeTAIR_b_FtEvapTmpFA_write_IRV: type=Boolean, init-value=0
          VeTAIR_T_FtEvapTmp_P1C_write_IRV: type=Float, init-value=0
          VeTAIR_b_FtEvapTmp_P1CFA_write_IRV: type=Boolean, init-value=0
          VeTAIR_T_FtEvapTmp_Tgt_write_IRV: type=Float, init-value=0
          VeTAIR_b_FtEvapTmp_TgtFA_write_IRV: type=Boolean, init-value=0
          VeTAIR_Pct_RrBlwrCmd_write_IRV: type=Float, init-value=0
          VeTAIR_Pct_FrtBlwrCmd_write_IRV: type=Float, init-value=0
          VeTAIR_b_FrtBlwrCmdFA_write_IRV: type=Boolean, init-value=0
          VeTAIR_T_VhIntTmp_write_IRV: type=Float, init-value=0
          VeTAIR_b_VhIntTmpFA_write_IRV: type=Boolean, init-value=0
          VeTAIR_T_HtrCoreTmp_Tgt_write_IRV: type=Float, init-value=0
          VeTAIR_b_WinshldDfrst_write_IRV: type=Boolean, init-value=0
          VeTAIF_e_CompSpdTgt_IO_CntrlSt_write_IRV: type=TeTAIR_e_IO_CntrlSt, init-value=CeTAIR_e_Return_Control_to_ECU
          VeTAIF_n_CompSpdTgt_write_IRV: type=Float, init-value=0
          VeTAIR_I_ECVD_HVACCabinReq_write_IRV: type=Float, init-value=0
          VeTAIR_b_ECVD_HVACCabinReqFA_write_IRV: type=Boolean, init-value=0
          VeTAIR_I_ECVD_HVACCurrentAct_write_IRV: type=Float, init-value=0
          VeTAIR_b_ECVD_HVACCurrentActFA_write_IRV: type=Boolean, init-value=0
          VeTAIR_e_ECM_AC_ClutchSts_write_IRV: type=TeTAIR_e_ECM_AC_ClutchSts, init-value=CeTAIR_e_ClutchSts_Default
          VeTAIR_b_ECM_AC_ClutchStsFA_write_IRV: type=Boolean, init-value=0
          VeTAIR_b_HghRfrgtPresFailStsFA_write_IRV: type=Boolean, init-value=0
          VeTAIR_b_AGS_BoostSts_write_IRV: type=Boolean, init-value=0
          VeTAIR_b_AGS_CalibrationActv_write_IRV: type=Boolean, init-value=0
          VeTAIR_b_AGS_ErrMechBreak_write_IRV: type=Boolean, init-value=0
          VeTAIR_b_AGS_ErrMechStuck_write_IRV: type=Boolean, init-value=0
          VeTAIR_b_AGS_ErrOverTemp_write_IRV: type=Boolean, init-value=0
          VeTAIR_b_AGS_ErrOverVolt_write_IRV: type=Boolean, init-value=0
          VeTAIR_b_AGS_ErrUnderVolt_write_IRV: type=Boolean, init-value=0
          VeTAIR_b_AGS_ResErr_write_IRV: type=Boolean, init-value=0
          VeTAIR_Pct_AGS_CurrPos_CAN_write_IRV: type=Float, init-value=0
          VeTAIR_b_AGS_CurrPosFA_write_IRV: type=Boolean, init-value=0
          VeTAIR_e_AGS_ErrFdb_write_IRV: type=TeTAIR_e_AGS_ErrLIN, init-value=CeTAIR_e_AGS_NO_ERROR
          VeTAIR_b_AGS_ErrFdbFA_write_IRV: type=Boolean, init-value=0
          VeTAIR_e_AGS_CalibrationSts_write_IRV: type=TeTAIR_e_AGS_Calibration_Sts, init-value=CeTAIR_e_AGS_NotCalibrated
          VeTAIR_b_AGS2_BoostSts_write_IRV: type=Boolean, init-value=0
          VeTAIR_b_AGS2_CalibrationActv_write_IRV: type=Boolean, init-value=0
          VeTAIR_b_AGS2_ErrMechBreak_write_IRV: type=Boolean, init-value=0
          VeTAIR_b_AGS2_ErrMechStuck_write_IRV: type=Boolean, init-value=0
          VeTAIR_b_AGS2_ErrOverTemp_write_IRV: type=Boolean, init-value=0
          VeTAIR_b_AGS2_ErrOverVolt_write_IRV: type=Boolean, init-value=0
          VeTAIR_b_AGS2_ErrUnderVolt_write_IRV: type=Boolean, init-value=0
          VeTAIR_b_AGS2_ResErr_write_IRV: type=Boolean, init-value=0
          VeTAIR_Pct_AGS2_CurrPos_CAN_write_IRV: type=Float, init-value=0
          VeTAIR_b_AGS2_CurrPosFA_write_IRV: type=Boolean, init-value=0
          VeTAIR_e_AGS2_ErrFdb_write_IRV: type=TeTAIR_e_AGS_ErrLIN, init-value=CeTAIR_e_AGS_NO_ERROR
          VeTAIR_b_AGS2_ErrFdbFA_write_IRV: type=Boolean, init-value=0
          VeTAIR_e_AGS2_CalibrationSts_write_IRV: type=TeTAIR_e_AGS_Calibration_Sts, init-value=CeTAIR_e_AGS_NotCalibrated
          VeTAIF_e_AGS_IO_CntrlSt_write_IRV: type=TeTAIR_e_IO_CntrlSt, init-value=CeTAIR_e_Return_Control_to_ECU
          VeTAIF_e_AGS_PstnCmnd_write_IRV: type=TeFSCR_e_AGS_PosRq, init-value=CeFSCR_e_Open100
          VeTAIF_b_DVC_AGS1_Calibration_Start_write_IRV: type=Boolean, init-value=0
          VeTAIF_e_AGS2_IO_CntrlSt_write_IRV: type=TeTAIR_e_IO_CntrlSt, init-value=CeTAIR_e_Return_Control_to_ECU
          VeTAIF_e_AGS2_PstnCmnd_write_IRV: type=TeFSCR_e_AGS_PosRq, init-value=CeFSCR_e_Open100
          VeTAIF_b_DVC_AGS2_Calibration_Start_write_IRV: type=Boolean, init-value=0
          VeTAIR_e_AGS_CurrPos_write_IRV: type=TeFSCR_e_AGS_PosRq, init-value=CeFSCR_e_Open100
          VeTAIR_e_AGS2_CurrPos_write_IRV: type=TeFSCR_e_AGS_PosRq, init-value=CeFSCR_e_Open100
          VeTAIR_e_RearDefrostSts_write_IRV: type=TeTAIR_e_RearDefrostSts, init-value=CeTAIR_e_RearDefrostSts_OFF
          VeTAIR_b_EBL_StatFA_write_IRV: type=Boolean, init-value=0
          VeTAIR_y_RearCabinFanSts_write_IRV: type=UInt8, init-value=0
          VeTAIR_b_RearCabinFanStsFA_write_IRV: type=Boolean, init-value=0
